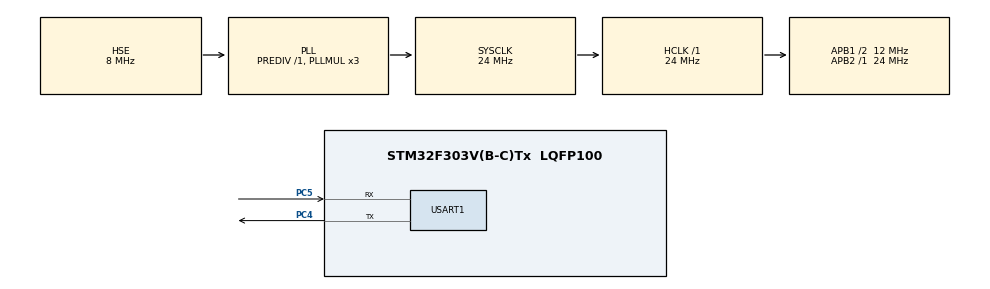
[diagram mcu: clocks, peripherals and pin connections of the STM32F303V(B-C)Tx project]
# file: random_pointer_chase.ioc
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Mcu.Family=STM32F3
Mcu.Name=STM32F303V(B-C)Tx
Mcu.Package=LQFP100
NVIC.PriorityGroup=NVIC_PRIORITYGROUP_4
NVIC.TIM2_IRQn=true\:0\:0\:false\:false\:true\:true\:true
PC4.Mode=Asynchronous
PC4.Signal=USART1_TX
PC5.Mode=Asynchronous
PC5.Signal=USART1_RX
PF0-OSC_IN.Mode=HSE-External-Oscillator
PF0-OSC_IN.Signal=RCC_OSC_IN
PF1-OSC_OUT.Mode=HSE-External-Oscillator
PF1-OSC_OUT.Signal=RCC_OSC_OUT
ProjectManager.HeapSize=0x200
ProjectManager.StackSize=0x400
ProjectManager.TargetToolchain=STM32CubeIDE
RCC.AHBFreq_Value=24000000
RCC.APB1CLKDivider=RCC_HCLK_DIV2
RCC.APB1Freq_Value=12000000
RCC.APB1TimFreq_Value=24000000
RCC.APB2Freq_Value=24000000
RCC.APB2TimFreq_Value=24000000
RCC.CortexFreq_Value=24000000
RCC.HCLKFreq_Value=24000000
RCC.HSE_VALUE=8000000
RCC.HSI_VALUE=8000000
RCC.LSE_VALUE=32768
RCC.PLLMUL=RCC_PLL_MUL3
RCC.PLLSourceVirtual=RCC_PLLSOURCE_HSE
RCC.SYSCLKFreq_VALUE=24000000
RCC.SYSCLKSourceVirtual=RCC_SYSCLKSOURCE_PLLCLK
RCC.USBFreq_Value=24000000
TIM2.AutoReloadPreload=TIM_AUTORELOAD_PRELOAD_DISABLE
TIM2.Period=(1000000-1)
TIM2.Prescaler=(24-1)
USART1.VirtualMode-Asynchronous=VM_ASYNC
VP_TIM2_VS_ClockSourceINT.Mode=Internal
board=custom

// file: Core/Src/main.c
/* USER CODE BEGIN Header */
/**
  ******************************************************************************
  * @file           : main.c
  * @brief          : Main program body
  ******************************************************************************
  * @attention
  *
  * <h2><center>&copy; Copyright (c) 2021 STMicroelectronics.
  * All rights reserved.</center></h2>
  *
  * This software component is licensed by ST under BSD 3-Clause license,
  * the "License"; You may not use this file except in compliance with the
  * License. You may obtain a copy of the License at:
  *                        opensource.org/licenses/BSD-3-Clause
  *
  ******************************************************************************
  */
/* USER CODE END Header */
#include "main.h"

/* USER CODE BEGIN Includes */

/*data size*/
#define POINTER_SIZE_2000

/*functions data*/
#define FUNCTIONS_DATA_ON_FLASH
//#define FUNCTIONS_DATA_ON_CCM

/*program allocation*/
#define PROGRAM_IN_CCM

/* USER CODE END Includes */

/* USER CODE BEGIN PTD */
#ifdef PROGRAM_IN_CCM
__attribute__((section(".ccmram")))
#endif
void random_pointer_chase_1000times( void * p0){
    void **this_pp = p0;
    for(int i = 0;i<1000;i++){
	  while(this_pp){
      this_pp = *this_pp;
	  }
    this_pp = p0;
  };

}

/* USER CODE END PTD */

/* USER CODE BEGIN PM */

#ifdef POINTER_SIZE_100
#ifdef FUNCTIONS_DATA_ON_CCM
  __attribute__((section(".ccmram")))
#endif
#ifdef FUNCTIONS_DATA_ON_FLASH
  const
#endif
   void *
#ifdef FUNCTIONS_DATA_ON_FLASH
  const
#endif
    pointers[100] = {
    &pointers[80], &pointers[65], &pointers[28], &pointers[92], &pointers[60], &pointers[22], &pointers[29], &pointers[21], &pointers[86], &pointers[79], &pointers[18], &pointers[56], &pointers[45], &pointers[35], &pointers[74], &pointers[48], &pointers[78], &pointers[67], &pointers[57], &pointers[71], &pointers[77], &pointers[15], &pointers[96], &pointers[43], &pointers[50], &pointers[20], &pointers[82], &pointers[58], &pointers[53], &pointers[47], &pointers[75], &pointers[3], &pointers[94], &pointers[95], &pointers[31], &pointers[44], &pointers[24], &pointers[23], &pointers[39], &pointers[37], &pointers[88], &pointers[97], &pointers[6], &pointers[52], &pointers[41], &pointers[55], &pointers[89], &pointers[76], &pointers[61], &pointers[70],
    &pointers[87], &pointers[30], &pointers[16], &pointers[36], &pointers[51], &pointers[25], &pointers[91], &pointers[17], &pointers[81], &pointers[34], &pointers[32], &pointers[90], &pointers[85], &pointers[11], &pointers[38], &pointers[99], &pointers[5], &pointers[1], &pointers[4], &pointers[59], &pointers[14], &pointers[13], &pointers[63], &pointers[27], &pointers[83], &pointers[8], &pointers[26], &pointers[73], &pointers[42], &pointers[62], &pointers[33], &pointers[66], &pointers[9], &pointers[2], &pointers[68], &pointers[93], &pointers[69], &pointers[10], &pointers[54], &pointers[84], &pointers[49], &pointers[19], NULL, &pointers[98], &pointers[7], &pointers[46], &pointers[64], &pointers[12], &pointers[40], &pointers[72]};

#endif

#ifdef POINTER_SIZE_200
#ifdef FUNCTIONS_DATA_ON_CCM
  __attribute__((section(".ccmram")))
#endif
#ifdef FUNCTIONS_DATA_ON_FLASH
  const
#endif
   void *
#ifdef FUNCTIONS_DATA_ON_FLASH
  const
#endif
    pointers[200] = {
    &pointers[160], &pointers[2], &pointers[54], &pointers[184], &pointers[56], &pointers[166], &pointers[93], &pointers[116], &pointers[120], &pointers[37], &pointers[176], &pointers[20], &pointers[179], &pointers[88], &pointers[41], &pointers[95], &pointers[97], &pointers[85], NULL, &pointers[36], &pointers[73], &pointers[7], &pointers[196], &pointers[191], &pointers[135], &pointers[82], &pointers[16], &pointers[147], &pointers[174], &pointers[96], &pointers[42], &pointers[35], &pointers[60], &pointers[34], &pointers[1], &pointers[103], &pointers[159], &pointers[123], &pointers[68], &pointers[173], &pointers[170], &pointers[29], &pointers[180], &pointers[158], &pointers[115], &pointers[198], &pointers[109], &pointers[100], &pointers[132], &pointers[156],
    &pointers[89], &pointers[139], &pointers[122], &pointers[172], &pointers[175], &pointers[104], &pointers[105], &pointers[15], &pointers[178], &pointers[69], &pointers[45], &pointers[13], &pointers[21], &pointers[171], &pointers[193], &pointers[28], &pointers[190], &pointers[50], &pointers[17], &pointers[25], &pointers[86], &pointers[101], &pointers[47], &pointers[62], &pointers[63], &pointers[81], &pointers[130], &pointers[6], &pointers[162], &pointers[124], &pointers[91], &pointers[51], &pointers[94], &pointers[65], &pointers[168], &pointers[78], &pointers[40], &pointers[141], &pointers[153], &pointers[125], &pointers[39], &pointers[79], &pointers[177], &pointers[107], &pointers[61], &pointers[59], &pointers[121], &pointers[32], &pointers[140], &pointers[77],
    &pointers[186], &pointers[199], &pointers[90], &pointers[119], &pointers[181], &pointers[72], &pointers[138], &pointers[157], &pointers[161], &pointers[52], &pointers[195], &pointers[126], &pointers[148], &pointers[169], &pointers[33], &pointers[133], &pointers[118], &pointers[102], &pointers[117], &pointers[18], &pointers[64], &pointers[189], &pointers[71], &pointers[150], &pointers[155], &pointers[185], &pointers[11], &pointers[24], &pointers[3], &pointers[149], &pointers[143], &pointers[67], &pointers[183], &pointers[113], &pointers[23], &pointers[26], &pointers[8], &pointers[112], &pointers[163], &pointers[53], &pointers[27], &pointers[80], &pointers[129], &pointers[5], &pointers[131], &pointers[57], &pointers[145], &pointers[182], &pointers[146], &pointers[187],
    &pointers[165], &pointers[49], &pointers[192], &pointers[144], &pointers[99], &pointers[48], &pointers[108], &pointers[38], &pointers[75], &pointers[188], &pointers[66], &pointers[58], &pointers[87], &pointers[31], &pointers[128], &pointers[83], &pointers[12], &pointers[136], &pointers[70], &pointers[84], &pointers[111], &pointers[22], &pointers[154], &pointers[152], &pointers[110], &pointers[43], &pointers[74], &pointers[197], &pointers[127], &pointers[44], &pointers[10], &pointers[137], &pointers[4], &pointers[134], &pointers[46], &pointers[106], &pointers[19], &pointers[76], &pointers[114], &pointers[98], &pointers[92], &pointers[164], &pointers[30], &pointers[14], &pointers[142], &pointers[55], &pointers[9], &pointers[167], &pointers[194], &pointers[151]};
#endif

#ifdef POINTER_SIZE_300
#ifdef FUNCTIONS_DATA_ON_CCM
  __attribute__((section(".ccmram")))
#endif
#ifdef FUNCTIONS_DATA_ON_FLASH
  const
#endif
   void *
#ifdef FUNCTIONS_DATA_ON_FLASH
  const
#endif
    pointers[300] = {
    &pointers[131], &pointers[3], &pointers[204], &pointers[108], &pointers[99], &pointers[141], &pointers[192], &pointers[111], &pointers[77], &pointers[61], &pointers[268], &pointers[166], &pointers[185], &pointers[172], &pointers[74], &pointers[239], &pointers[246], &pointers[267], &pointers[83], &pointers[159], &pointers[231], &pointers[264], &pointers[262], &pointers[232], &pointers[54], &pointers[190], &pointers[165], &pointers[81], &pointers[245], &pointers[113], &pointers[251], &pointers[194], &pointers[295], &pointers[167], &pointers[145], &pointers[225], &pointers[256], &pointers[72], &pointers[297], &pointers[177], &pointers[229], &pointers[57], &pointers[13], &pointers[240], &pointers[112], &pointers[248], &pointers[296], &pointers[160], &pointers[234], &pointers[147],
    &pointers[20], &pointers[31], &pointers[211], &pointers[294], &pointers[88], &pointers[205], &pointers[26], &pointers[283], &pointers[191], &pointers[244], &pointers[136], &pointers[243], &pointers[218], &pointers[119], &pointers[142], &pointers[68], &pointers[6], &pointers[56], &pointers[1], &pointers[23], &pointers[293], &pointers[140], &pointers[228], &pointers[285], &pointers[169], &pointers[207], &pointers[10], &pointers[233], &pointers[210], &pointers[124], &pointers[91], &pointers[58], &pointers[37], &pointers[299], &pointers[196], &pointers[86], &pointers[149], &pointers[250], &pointers[278], &pointers[132], &pointers[126], &pointers[247], &pointers[217], &pointers[252], &pointers[200], &pointers[76], &pointers[170], &pointers[265], &pointers[291], &pointers[41],
    &pointers[173], &pointers[197], &pointers[105], &pointers[11], &pointers[5], &pointers[286], &pointers[287], &pointers[43], &pointers[282], &pointers[263], &pointers[222], &pointers[209], &pointers[96], &pointers[130], &pointers[55], &pointers[84], &pointers[257], &pointers[216], &pointers[98], &pointers[89], &pointers[224], &pointers[181], &pointers[29], &pointers[180], &pointers[179], &pointers[175], &pointers[50], &pointers[195], &pointers[27], &pointers[298], &pointers[189], &pointers[184], &pointers[237], &pointers[120], &pointers[178], &pointers[273], &pointers[255], &pointers[220], &pointers[33], &pointers[8], &pointers[188], &pointers[202], &pointers[134], &pointers[198], &pointers[94], &pointers[148], &pointers[164], &pointers[69], &pointers[106], &pointers[161],
    &pointers[36], &pointers[271], &pointers[109], &pointers[12], &pointers[137], &pointers[151], &pointers[143], &pointers[93], &pointers[163], &pointers[49], &pointers[51], &pointers[102], &pointers[45], &pointers[249], &pointers[115], &pointers[59], &pointers[213], &pointers[183], &pointers[103], &pointers[206], &pointers[16], &pointers[288], &pointers[154], &pointers[158], &pointers[182], &pointers[123], &pointers[277], &pointers[230], &pointers[236], &pointers[292], &pointers[75], &pointers[46], &pointers[87], &pointers[60], &pointers[272], &pointers[107], &pointers[71], &pointers[34], &pointers[238], &pointers[212], &pointers[67], &pointers[241], &pointers[92], &pointers[254], &pointers[63], &pointers[279], &pointers[284], &pointers[153], &pointers[125], &pointers[150],
    &pointers[82], &pointers[259], &pointers[269], &pointers[35], &pointers[138], &pointers[133], &pointers[25], &pointers[52], &pointers[152], &pointers[144], &pointers[155], &pointers[19], &pointers[139], &pointers[114], &pointers[4], &pointers[18], &pointers[281], &pointers[104], &pointers[274], &pointers[40], &pointers[9], &pointers[28], &pointers[70], &pointers[95], &pointers[110], &pointers[260], &pointers[171], &pointers[21], &pointers[65], &pointers[275], &pointers[42], &pointers[215], &pointers[64], &pointers[214], &pointers[121], &pointers[227], &pointers[203], &pointers[135], &pointers[176], &pointers[128], &pointers[38], &pointers[127], &pointers[280], &pointers[201], &pointers[32], &pointers[223], &pointers[290], &pointers[79], &pointers[73], &pointers[219],
    &pointers[80], &pointers[253], &pointers[186], NULL, &pointers[168], &pointers[162], &pointers[146], &pointers[289], &pointers[174], &pointers[117], &pointers[129], &pointers[97], &pointers[30], &pointers[100], &pointers[39], &pointers[270], &pointers[187], &pointers[78], &pointers[24], &pointers[261], &pointers[116], &pointers[258], &pointers[15], &pointers[221], &pointers[90], &pointers[199], &pointers[156], &pointers[235], &pointers[157], &pointers[53], &pointers[14], &pointers[226], &pointers[85], &pointers[242], &pointers[2], &pointers[118], &pointers[101], &pointers[44], &pointers[266], &pointers[47], &pointers[276], &pointers[193], &pointers[48], &pointers[62], &pointers[7], &pointers[22], &pointers[66], &pointers[17], &pointers[208], &pointers[122]};
#endif

#ifdef POINTER_SIZE_400
#ifdef FUNCTIONS_DATA_ON_CCM
  __attribute__((section(".ccmram")))
#endif
#ifdef FUNCTIONS_DATA_ON_FLASH
  const
#endif
   void *
#ifdef FUNCTIONS_DATA_ON_FLASH
  const
#endif
    pointers[400] = {
    &pointers[319], &pointers[3], &pointers[306], &pointers[108], &pointers[171], &pointers[232], &pointers[376], &pointers[375], &pointers[345], &pointers[381], &pointers[282], &pointers[223], &pointers[185], &pointers[221], &pointers[35], &pointers[239], &pointers[217], &pointers[122], &pointers[318], &pointers[222], &pointers[55], &pointers[257], NULL, &pointers[303], &pointers[93], &pointers[42], &pointers[18], &pointers[81], &pointers[44], &pointers[268], &pointers[132], &pointers[168], &pointers[176], &pointers[397], &pointers[170], &pointers[220], &pointers[394], &pointers[72], &pointers[261], &pointers[16], &pointers[320], &pointers[77], &pointers[208], &pointers[51], &pointers[112], &pointers[116], &pointers[395], &pointers[107], &pointers[160], &pointers[341],
    &pointers[4], &pointers[204], &pointers[36], &pointers[294], &pointers[60], &pointers[323], &pointers[189], &pointers[240], &pointers[191], &pointers[140], &pointers[313], &pointers[126], &pointers[271], &pointers[286], &pointers[256], &pointers[68], &pointers[147], &pointers[252], &pointers[1], &pointers[100], &pointers[399], &pointers[262], &pointers[317], &pointers[21], &pointers[205], &pointers[136], &pointers[288], &pointers[329], &pointers[283], &pointers[351], &pointers[64], &pointers[58], &pointers[37], &pointers[25], &pointers[190], &pointers[86], &pointers[149], &pointers[290], &pointers[167], &pointers[349], &pointers[173], &pointers[30], &pointers[178], &pointers[347], &pointers[200], &pointers[326], &pointers[39], &pointers[211], &pointers[295], &pointers[324],
    &pointers[331], &pointers[197], &pointers[277], &pointers[32], &pointers[38], &pointers[371], &pointers[28], &pointers[175], &pointers[374], &pointers[146], &pointers[382], &pointers[209], &pointers[96], &pointers[212], &pointers[314], &pointers[322], &pointers[311], &pointers[274], &pointers[52], &pointers[74], &pointers[291], &pointers[104], &pointers[393], &pointers[71], &pointers[307], &pointers[266], &pointers[237], &pointers[195], &pointers[333], &pointers[302], &pointers[270], &pointers[380], &pointers[344], &pointers[296], &pointers[236], &pointers[80], &pointers[34], &pointers[46], &pointers[130], &pointers[124], &pointers[308], &pointers[265], &pointers[280], &pointers[66], &pointers[94], &pointers[244], &pointers[305], &pointers[224], &pointers[259], &pointers[161],
    &pointers[392], &pointers[337], &pointers[19], &pointers[12], &pointers[14], &pointers[309], &pointers[198], &pointers[247], &pointers[114], &pointers[182], &pointers[163], &pointers[102], &pointers[95], &pointers[327], &pointers[316], &pointers[89], &pointers[370], &pointers[287], &pointers[281], &pointers[335], &pointers[155], &pointers[22], &pointers[289], &pointers[165], &pointers[338], &pointers[300], &pointers[358], &pointers[263], &pointers[151], &pointers[98], &pointers[275], &pointers[258], &pointers[157], &pointers[59], &pointers[354], &pointers[213], &pointers[76], &pointers[369], &pointers[193], &pointers[152], &pointers[225], &pointers[241], &pointers[293], &pointers[297], &pointers[315], &pointers[279], &pointers[346], &pointers[153], &pointers[246], &pointers[92],
    &pointers[82], &pointers[141], &pointers[106], &pointers[120], &pointers[226], &pointers[166], &pointers[363], &pointers[10], &pointers[17], &pointers[144], &pointers[26], &pointers[137], &pointers[57], &pointers[357], &pointers[33], &pointers[188], &pointers[340], &pointers[359], &pointers[196], &pointers[245], &pointers[139], &pointers[143], &pointers[47], &pointers[385], &pointers[235], &pointers[119], &pointers[73], &pointers[383], &pointers[65], &pointers[365], &pointers[202], &pointers[284], &pointers[24], &pointers[278], &pointers[216], &pointers[384], &pointers[125], &pointers[177], &pointers[88], &pointers[128], &pointers[11], &pointers[127], &pointers[91], &pointers[386], &pointers[330], &pointers[134], &pointers[304], &pointers[162], &pointers[83], &pointers[362],
    &pointers[99], &pointers[250], &pointers[312], &pointers[172], &pointers[353], &pointers[388], &pointers[179], &pointers[233], &pointers[367], &pointers[138], &pointers[273], &pointers[97], &pointers[121], &pointers[328], &pointers[110], &pointers[332], &pointers[187], &pointers[206], &pointers[253], &pointers[129], &pointers[264], &pointers[169], &pointers[15], &pointers[199], &pointers[219], &pointers[231], &pointers[113], &pointers[348], &pointers[390], &pointers[53], &pointers[48], &pointers[361], &pointers[215], &pointers[373], &pointers[210], &pointers[368], &pointers[214], &pointers[355], &pointers[142], &pointers[67], &pointers[23], &pointers[150], &pointers[180], &pointers[352], &pointers[389], &pointers[364], &pointers[339], &pointers[5], &pointers[156], &pointers[45],
    &pointers[186], &pointers[2], &pointers[56], &pointers[70], &pointers[103], &pointers[115], &pointers[174], &pointers[62], &pointers[243], &pointers[301], &pointers[234], &pointers[356], &pointers[145], &pointers[49], &pointers[63], &pointers[343], &pointers[109], &pointers[366], &pointers[148], &pointers[131], &pointers[6], &pointers[105], &pointers[13], &pointers[255], &pointers[227], &pointers[230], &pointers[242], &pointers[350], &pointers[269], &pointers[248], &pointers[325], &pointers[292], &pointers[260], &pointers[27], &pointers[272], &pointers[54], &pointers[298], &pointers[9], &pointers[159], &pointers[43], &pointers[29], &pointers[194], &pointers[20], &pointers[387], &pointers[396], &pointers[276], &pointers[254], &pointers[61], &pointers[321], &pointers[299],
    &pointers[41], &pointers[372], &pointers[158], &pointers[135], &pointers[379], &pointers[360], &pointers[133], &pointers[75], &pointers[183], &pointers[285], &pointers[267], &pointers[118], &pointers[229], &pointers[84], &pointers[398], &pointers[238], &pointers[228], &pointers[249], &pointers[117], &pointers[123], &pointers[90], &pointers[101], &pointers[181], &pointers[8], &pointers[85], &pointers[111], &pointers[50], &pointers[87], &pointers[218], &pointers[334], &pointers[184], &pointers[79], &pointers[336], &pointers[378], &pointers[203], &pointers[154], &pointers[342], &pointers[31], &pointers[192], &pointers[7], &pointers[78], &pointers[164], &pointers[69], &pointers[310], &pointers[391], &pointers[377], &pointers[207], &pointers[251], &pointers[40], &pointers[201]};

#endif

#ifdef POINTER_SIZE_500
#ifdef FUNCTIONS_DATA_ON_CCM
  __attribute__((section(".ccmram")))
#endif
#ifdef FUNCTIONS_DATA_ON_FLASH
  const
#endif
   void *
#ifdef FUNCTIONS_DATA_ON_FLASH
  const
#endif
    pointers[500] = {
    &pointers[319], &pointers[447], &pointers[306], &pointers[108], &pointers[16], &pointers[232], &pointers[243], &pointers[375], &pointers[291], &pointers[218], &pointers[282], &pointers[121], &pointers[185], &pointers[118], &pointers[35], &pointers[492], &pointers[425], &pointers[122], &pointers[351], &pointers[222], &pointers[469], &pointers[286], &pointers[430], &pointers[382], &pointers[413], &pointers[42], &pointers[114], &pointers[462], &pointers[84], &pointers[327], &pointers[132], &pointers[332], &pointers[38], &pointers[183], &pointers[170], &pointers[330], &pointers[345], &pointers[72], &pointers[340], &pointers[275], &pointers[63], &pointers[435], &pointers[308], &pointers[51], &pointers[158], &pointers[202], &pointers[252], &pointers[107], &pointers[160], &pointers[66],
    &pointers[323], &pointers[457], &pointers[346], &pointers[294], &pointers[446], &pointers[87], &pointers[302], &pointers[472], &pointers[191], &pointers[206], &pointers[45], &pointers[126], &pointers[4], &pointers[119], &pointers[488], &pointers[68], &pointers[168], &pointers[289], &pointers[1], &pointers[466], &pointers[388], &pointers[112], &pointers[317], &pointers[233], &pointers[316], &pointers[136], &pointers[396], &pointers[410], &pointers[432], &pointers[74], &pointers[314], &pointers[58], &pointers[391], &pointers[25], &pointers[139], &pointers[86], &pointers[149], &pointers[223], &pointers[480], &pointers[231], &pointers[98], &pointers[30], &pointers[256], &pointers[320], &pointers[474], &pointers[407], &pointers[448], &pointers[110], &pointers[421], &pointers[156],
    &pointers[109], &pointers[197], &pointers[277], &pointers[418], &pointers[454], &pointers[479], &pointers[221], &pointers[175], &pointers[397], &pointers[355], &pointers[443], &pointers[209], &pointers[487], &pointers[259], &pointers[415], &pointers[125], &pointers[60], &pointers[69], &pointers[261], &pointers[230], &pointers[90], &pointers[299], &pointers[305], &pointers[295], &pointers[50], &pointers[328], &pointers[237], &pointers[195], &pointers[333], &pointers[378], &pointers[344], &pointers[380], &pointers[428], &pointers[171], &pointers[303], &pointers[100], &pointers[34], &pointers[467], &pointers[404], &pointers[192], &pointers[264], &pointers[150], &pointers[280], &pointers[64], &pointers[94], &pointers[138], &pointers[99], &pointers[255], &pointers[257], &pointers[161],
    &pointers[475], &pointers[73], &pointers[19], &pointers[12], &pointers[28], &pointers[419], &pointers[324], &pointers[247], &pointers[459], &pointers[182], &pointers[352], &pointers[102], &pointers[95], &pointers[495], &pointers[70], &pointers[322], &pointers[71], &pointers[304], &pointers[227], &pointers[134], &pointers[155], &pointers[461], &pointers[364], &pointers[468], &pointers[422], &pointers[376], &pointers[217], &pointers[263], &pointers[21], &pointers[270], &pointers[89], &pointers[145], &pointers[157], &pointers[18], &pointers[408], &pointers[213], &pointers[76], &pointers[463], &pointers[193], &pointers[152], &pointers[146], &pointers[241], &pointers[356], &pointers[297], &pointers[273], &pointers[279], &pointers[455], &pointers[153], &pointers[245], &pointers[366],
    &pointers[82], &pointers[342], &pointers[203], &pointers[389], &pointers[137], &pointers[385], &pointers[402], &pointers[10], &pointers[17], &pointers[144], &pointers[180], &pointers[96], &pointers[55], &pointers[442], &pointers[262], &pointers[188], &pointers[424], &pointers[405], &pointers[244], &pointers[123], &pointers[336], &pointers[416], &pointers[47], &pointers[476], &pointers[9], &pointers[154], &pointers[307], &pointers[103], &pointers[65], &pointers[360], &pointers[452], &pointers[288], &pointers[24], &pointers[499], &pointers[216], &pointers[130], &pointers[481], &pointers[177], &pointers[148], &pointers[398], &pointers[219], &pointers[445], &pointers[361], &pointers[490], &pointers[491], &pointers[374], &pointers[141], &pointers[357], &pointers[83], &pointers[423],
    &pointers[353], &pointers[43], &pointers[140], &pointers[172], &pointers[104], &pointers[59], &pointers[412], &pointers[284], &pointers[427], &pointers[271], &pointers[115], &pointers[226], &pointers[337], &pointers[456], &pointers[281], &pointers[22], &pointers[420], &pointers[287], &pointers[311], &pointers[129], &pointers[335], &pointers[365], &pointers[15], &pointers[92], &pointers[208], &pointers[438], &pointers[166], &pointers[348], &pointers[251], &pointers[53], &pointers[48], &pointers[258], &pointers[215], &pointers[106], &pointers[179], &pointers[54], &pointers[267], &pointers[325], &pointers[326], &pointers[449], &pointers[484], &pointers[349], &pointers[201], &pointers[240], &pointers[482], &pointers[178], &pointers[6], &pointers[5], &pointers[439], &pointers[329],
    &pointers[290], &pointers[2], &pointers[189], &pointers[20], &pointers[238], &pointers[377], &pointers[436], &pointers[79], &pointers[274], &pointers[301], &pointers[236], &pointers[250], &pointers[278], &pointers[186], &pointers[32], &pointers[450], &pointers[371], &pointers[453], &pointers[205], &pointers[131], &pointers[486], &pointers[105], &pointers[116], &pointers[460], &pointers[173], &pointers[44], &pointers[312], &pointers[338], &pointers[39], &pointers[14], &pointers[458], &pointers[190], &pointers[151], &pointers[27], &pointers[473], &pointers[210], &pointers[292], &pointers[265], &pointers[253], &pointers[489], &pointers[381], &pointers[181], &pointers[315], &pointers[300], &pointers[260], &pointers[390], &pointers[478], &pointers[31], &pointers[321], &pointers[437],
    &pointers[411], &pointers[187], &pointers[163], &pointers[246], &pointers[483], &pointers[276], &pointers[97], &pointers[162], &pointers[296], &pointers[477], &pointers[198], &pointers[91], &pointers[229], &pointers[174], &pointers[67], &pointers[57], &pointers[164], &pointers[368], &pointers[470], &pointers[26], &pointers[225], &pointers[414], &pointers[52], &pointers[234], &pointers[386], &pointers[111], &pointers[313], &pointers[373], &pointers[56], &pointers[334], &pointers[184], &pointers[283], &pointers[88], &pointers[46], &pointers[496], &pointers[370], &pointers[343], &pointers[169], &pointers[8], &pointers[147], &pointers[387], &pointers[409], &pointers[367], &pointers[200], &pointers[359], &pointers[11], &pointers[142], &pointers[465], &pointers[493], &pointers[362],
    &pointers[41], &pointers[358], &pointers[266], &pointers[318], &pointers[196], &pointers[395], &pointers[199], &pointers[242], &pointers[354], &pointers[37], &pointers[248], &pointers[341], &pointers[383], &pointers[93], &pointers[417], &pointers[13], &pointers[117], &pointers[214], &pointers[441], &pointers[309], &pointers[372], &pointers[392], &pointers[159], &pointers[401], &pointers[29], &pointers[80], &pointers[124], &pointers[33], &pointers[384], &pointers[298], &pointers[49], &pointers[379], &pointers[406], &pointers[204], &pointers[399], &pointers[77], &pointers[363], &pointers[113], &pointers[485], &pointers[403], &pointers[133], &pointers[224], &pointers[75], &pointers[339], &pointers[23], &pointers[127], &pointers[498], &pointers[3], &pointers[254], &pointers[212],
    &pointers[369], &pointers[429], &pointers[62], &pointers[228], &pointers[434], &pointers[451], &pointers[269], &pointers[293], &pointers[426], &pointers[440], &pointers[471], &pointers[78], &pointers[81], &pointers[249], &pointers[40], &pointers[85], &pointers[36], &pointers[444], &pointers[285], &pointers[143], &pointers[497], &pointers[120], &pointers[176], &pointers[272], &pointers[393], &pointers[394], &pointers[347], &pointers[194], &pointers[220], &pointers[494], &pointers[135], &pointers[350], &pointers[7], &pointers[431], &pointers[310], &pointers[165], &pointers[61], NULL, &pointers[235], &pointers[331], &pointers[167], &pointers[433], &pointers[239], &pointers[128], &pointers[101], &pointers[400], &pointers[207], &pointers[211], &pointers[464], &pointers[268]};
#endif

#ifdef POINTER_SIZE_750
#ifdef FUNCTIONS_DATA_ON_CCM
  __attribute__((section(".ccmram")))
#endif
#ifdef FUNCTIONS_DATA_ON_FLASH
  const
#endif
   void *
#ifdef FUNCTIONS_DATA_ON_FLASH
  const
#endif
    pointers[750] = {
    &pointers[638], &pointers[558], &pointers[6], &pointers[436], &pointers[611], &pointers[168], &pointers[215], &pointers[423], &pointers[428], &pointers[564], &pointers[464], &pointers[520], &pointers[486], &pointers[63], &pointers[222], &pointers[235], &pointers[682], &pointers[313], &pointers[237], &pointers[563], &pointers[580], &pointers[70], &pointers[327], &pointers[370], &pointers[367], &pointers[567], &pointers[64], &pointers[261], &pointers[457], &pointers[201], &pointers[477], &pointers[84], &pointers[352], &pointers[244], &pointers[506], &pointers[599], &pointers[628], &pointers[644], &pointers[444], &pointers[733], &pointers[41], &pointers[542], &pointers[341], &pointers[483], &pointers[619], &pointers[403], &pointers[332], &pointers[552], &pointers[186], &pointers[635],
    &pointers[83], &pointers[410], &pointers[51], &pointers[460], &pointers[161], &pointers[304], &pointers[167], &pointers[163], &pointers[34], &pointers[263], &pointers[112], &pointers[431], &pointers[249], &pointers[338], &pointers[402], &pointers[365], &pointers[268], &pointers[340], &pointers[318], &pointers[57], &pointers[521], &pointers[379], &pointers[42], &pointers[568], &pointers[143], &pointers[86], &pointers[391], &pointers[703], &pointers[259], &pointers[218], &pointers[565], &pointers[153], &pointers[451], &pointers[616], &pointers[200], &pointers[404], &pointers[408], &pointers[258], &pointers[22], &pointers[291], &pointers[536], &pointers[254], &pointers[504], &pointers[248], &pointers[214], &pointers[320], &pointers[117], &pointers[91], &pointers[8], &pointers[307],
    &pointers[744], &pointers[576], &pointers[509], &pointers[570], &pointers[344], &pointers[588], &pointers[355], NULL, &pointers[389], &pointers[337], &pointers[173], &pointers[604], &pointers[321], &pointers[508], &pointers[592], &pointers[584], &pointers[381], &pointers[189], &pointers[137], &pointers[123], &pointers[229], &pointers[131], &pointers[252], &pointers[430], &pointers[514], &pointers[243], &pointers[587], &pointers[27], &pointers[630], &pointers[586], &pointers[136], &pointers[534], &pointers[360], &pointers[606], &pointers[578], &pointers[308], &pointers[2], &pointers[44], &pointers[80], &pointers[518], &pointers[388], &pointers[125], &pointers[66], &pointers[633], &pointers[743], &pointers[465], &pointers[709], &pointers[721], &pointers[685], &pointers[466],
    &pointers[271], &pointers[737], &pointers[658], &pointers[317], &pointers[591], &pointers[49], &pointers[479], &pointers[478], &pointers[655], &pointers[455], &pointers[405], &pointers[116], &pointers[384], &pointers[623], &pointers[74], &pointers[217], &pointers[50], &pointers[529], &pointers[88], &pointers[468], &pointers[171], &pointers[297], &pointers[701], &pointers[445], &pointers[535], &pointers[230], &pointers[663], &pointers[461], &pointers[188], &pointers[223], &pointers[195], &pointers[59], &pointers[81], &pointers[12], &pointers[512], &pointers[92], &pointers[639], &pointers[399], &pointers[311], &pointers[503], &pointers[679], &pointers[686], &pointers[1], &pointers[220], &pointers[106], &pointers[690], &pointers[458], &pointers[82], &pointers[376], &pointers[627],
    &pointers[617], &pointers[722], &pointers[393], &pointers[632], &pointers[553], &pointers[688], &pointers[471], &pointers[569], &pointers[720], &pointers[596], &pointers[724], &pointers[652], &pointers[620], &pointers[134], &pointers[349], &pointers[221], &pointers[264], &pointers[142], &pointers[300], &pointers[459], &pointers[727], &pointers[170], &pointers[418], &pointers[411], &pointers[194], &pointers[572], &pointers[539], &pointers[120], &pointers[126], &pointers[556], &pointers[608], &pointers[400], &pointers[694], &pointers[740], &pointers[438], &pointers[335], &pointers[551], &pointers[729], &pointers[443], &pointers[180], &pointers[73], &pointers[351], &pointers[160], &pointers[548], &pointers[609], &pointers[102], &pointers[363], &pointers[198], &pointers[100], &pointers[294],
    &pointers[26], &pointers[138], &pointers[474], &pointers[390], &pointers[75], &pointers[129], &pointers[665], &pointers[654], &pointers[292], &pointers[149], &pointers[199], &pointers[738], &pointers[368], &pointers[24], &pointers[293], &pointers[530], &pointers[331], &pointers[462], &pointers[72], &pointers[348], &pointers[90], &pointers[67], &pointers[301], &pointers[725], &pointers[422], &pointers[96], &pointers[677], &pointers[453], &pointers[29], &pointers[528], &pointers[672], &pointers[299], &pointers[315], &pointers[559], &pointers[234], &pointers[555], &pointers[127], &pointers[187], &pointers[498], &pointers[329], &pointers[637], &pointers[519], &pointers[396], &pointers[159], &pointers[119], &pointers[678], &pointers[513], &pointers[322], &pointers[579], &pointers[482],
    &pointers[523], &pointers[634], &pointers[145], &pointers[38], &pointers[540], &pointers[603], &pointers[23], &pointers[316], &pointers[121], &pointers[618], &pointers[278], &pointers[546], &pointers[47], &pointers[575], &pointers[493], &pointers[155], &pointers[39], &pointers[496], &pointers[364], &pointers[228], &pointers[325], &pointers[140], &pointers[204], &pointers[449], &pointers[190], &pointers[680], &pointers[491], &pointers[726], &pointers[705], &pointers[276], &pointers[412], &pointers[524], &pointers[554], &pointers[247], &pointers[583], &pointers[148], &pointers[650], &pointers[739], &pointers[319], &pointers[487], &pointers[309], &pointers[336], &pointers[104], &pointers[213], &pointers[330], &pointers[645], &pointers[139], &pointers[68], &pointers[585], &pointers[526],
    &pointers[676], &pointers[670], &pointers[595], &pointers[525], &pointers[419], &pointers[566], &pointers[124], &pointers[549], &pointers[108], &pointers[177], &pointers[60], &pointers[533], &pointers[661], &pointers[497], &pointers[314], &pointers[36], &pointers[357], &pointers[414], &pointers[708], &pointers[114], &pointers[425], &pointers[489], &pointers[152], &pointers[288], &pointers[605], &pointers[386], &pointers[394], &pointers[303], &pointers[32], &pointers[78], &pointers[472], &pointers[481], &pointers[625], &pointers[723], &pointers[362], &pointers[55], &pointers[593], &pointers[545], &pointers[358], &pointers[231], &pointers[557], &pointers[647], &pointers[328], &pointers[306], &pointers[101], &pointers[260], &pointers[707], &pointers[704], &pointers[251], &pointers[164],
    &pointers[286], &pointers[191], &pointers[113], &pointers[749], &pointers[648], &pointers[85], &pointers[397], &pointers[718], &pointers[270], &pointers[206], &pointers[356], &pointers[53], &pointers[689], &pointers[574], &pointers[19], &pointers[242], &pointers[33], &pointers[289], &pointers[287], &pointers[359], &pointers[691], &pointers[339], &pointers[598], &pointers[273], &pointers[110], &pointers[710], &pointers[502], &pointers[176], &pointers[219], &pointers[375], &pointers[511], &pointers[302], &pointers[693], &pointers[45], &pointers[207], &pointers[470], &pointers[507], &pointers[323], &pointers[469], &pointers[702], &pointers[216], &pointers[224], &pointers[494], &pointers[516], &pointers[94], &pointers[382], &pointers[600], &pointers[17], &pointers[13], &pointers[193],
    &pointers[56], &pointers[305], &pointers[659], &pointers[437], &pointers[385], &pointers[227], &pointers[130], &pointers[69], &pointers[245], &pointers[295], &pointers[383], &pointers[374], &pointers[433], &pointers[192], &pointers[48], &pointers[174], &pointers[135], &pointers[432], &pointers[89], &pointers[98], &pointers[732], &pointers[560], &pointers[255], &pointers[277], &pointers[353], &pointers[296], &pointers[522], &pointers[256], &pointers[342], &pointers[527], &pointers[748], &pointers[253], &pointers[669], &pointers[232], &pointers[181], &pointers[250], &pointers[612], &pointers[450], &pointers[501], &pointers[290], &pointers[643], &pointers[281], &pointers[109], &pointers[324], &pointers[144], &pointers[577], &pointers[166], &pointers[197], &pointers[272], &pointers[607],
    &pointers[326], &pointers[282], &pointers[488], &pointers[46], &pointers[279], &pointers[133], &pointers[343], &pointers[624], &pointers[446], &pointers[312], &pointers[735], &pointers[532], &pointers[684], &pointers[366], &pointers[440], &pointers[696], &pointers[350], &pointers[77], &pointers[99], &pointers[16], &pointers[158], &pointers[7], &pointers[71], &pointers[25], &pointers[594], &pointers[681], &pointers[626], &pointers[582], &pointers[562], &pointers[473], &pointers[666], &pointers[146], &pointers[687], &pointers[345], &pointers[434], &pointers[590], &pointers[203], &pointers[31], &pointers[257], &pointers[492], &pointers[629], &pointers[226], &pointers[407], &pointers[30], &pointers[103], &pointers[184], &pointers[107], &pointers[416], &pointers[398], &pointers[354],
    &pointers[241], &pointers[651], &pointers[421], &pointers[695], &pointers[5], &pointers[442], &pointers[621], &pointers[105], &pointers[208], &pointers[95], &pointers[18], &pointers[37], &pointers[515], &pointers[429], &pointers[154], &pointers[406], &pointers[369], &pointers[118], &pointers[698], &pointers[275], &pointers[128], &pointers[622], &pointers[43], &pointers[541], &pointers[717], &pointers[730], &pointers[499], &pointers[132], &pointers[715], &pointers[674], &pointers[640], &pointers[417], &pointers[415], &pointers[475], &pointers[480], &pointers[454], &pointers[11], &pointers[21], &pointers[741], &pointers[298], &pointers[500], &pointers[274], &pointers[490], &pointers[10], &pointers[9], &pointers[692], &pointers[667], &pointers[615], &pointers[435], &pointers[697],
    &pointers[517], &pointers[4], &pointers[734], &pointers[380], &pointers[377], &pointers[531], &pointers[550], &pointers[156], &pointers[269], &pointers[653], &pointers[179], &pointers[347], &pointers[334], &pointers[426], &pointers[246], &pointers[266], &pointers[547], &pointers[87], &pointers[601], &pointers[361], &pointers[35], &pointers[40], &pointers[76], &pointers[93], &pointers[736], &pointers[61], &pointers[372], &pointers[20], &pointers[373], &pointers[97], &pointers[178], &pointers[212], &pointers[711], &pointers[719], &pointers[183], &pointers[280], &pointers[205], &pointers[427], &pointers[262], &pointers[700], &pointers[746], &pointers[210], &pointers[673], &pointers[544], &pointers[731], &pointers[485], &pointers[239], &pointers[505], &pointers[413], &pointers[467],
    &pointers[169], &pointers[172], &pointers[209], &pointers[649], &pointers[111], &pointers[147], &pointers[747], &pointers[495], &pointers[283], &pointers[225], &pointers[52], &pointers[476], &pointers[671], &pointers[310], &pointers[714], &pointers[54], &pointers[610], &pointers[657], &pointers[543], &pointers[151], &pointers[447], &pointers[378], &pointers[589], &pointers[613], &pointers[420], &pointers[699], &pointers[683], &pointers[240], &pointers[333], &pointers[484], &pointers[182], &pointers[538], &pointers[233], &pointers[664], &pointers[185], &pointers[157], &pointers[742], &pointers[346], &pointers[713], &pointers[573], &pointers[561], &pointers[712], &pointers[62], &pointers[58], &pointers[28], &pointers[641], &pointers[65], &pointers[285], &pointers[196], &pointers[236],
    &pointers[122], &pointers[395], &pointers[642], &pointers[631], &pointers[597], &pointers[675], &pointers[371], &pointers[401], &pointers[668], &pointers[706], &pointers[150], &pointers[571], &pointers[581], &pointers[510], &pointers[716], &pointers[424], &pointers[284], &pointers[79], &pointers[165], &pointers[456], &pointers[439], &pointers[448], &pointers[452], &pointers[267], &pointers[202], &pointers[141], &pointers[662], &pointers[602], &pointers[238], &pointers[441], &pointers[660], &pointers[656], &pointers[728], &pointers[175], &pointers[614], &pointers[162], &pointers[115], &pointers[387], &pointers[265], &pointers[409], &pointers[537], &pointers[14], &pointers[211], &pointers[636], &pointers[745], &pointers[646], &pointers[3], &pointers[463], &pointers[15], &pointers[392]};

#endif

#ifdef POINTER_SIZE_1000
#ifdef FUNCTIONS_DATA_ON_CCM
  __attribute__((section(".ccmram")))
#endif
#ifdef FUNCTIONS_DATA_ON_FLASH
  const
#endif
   void *
#ifdef FUNCTIONS_DATA_ON_FLASH
  const
#endif
    pointers[1000] = {
    &pointers[638], &pointers[719], &pointers[893], &pointers[259], &pointers[611], &pointers[542], &pointers[215], &pointers[86], &pointers[674], &pointers[996], &pointers[464], &pointers[408], &pointers[486], &pointers[469], &pointers[749], &pointers[610], &pointers[692], &pointers[949], &pointers[103], &pointers[563], &pointers[917], &pointers[327], &pointers[238], &pointers[370], &pointers[768], &pointers[125], &pointers[64], &pointers[342], &pointers[476], &pointers[201], &pointers[861], &pointers[737], &pointers[608], &pointers[244], &pointers[506], &pointers[762], &pointers[836], &pointers[426], &pointers[444], &pointers[216], &pointers[316], &pointers[140], &pointers[413], &pointers[483], &pointers[530], &pointers[441], &pointers[346], &pointers[162], &pointers[909], &pointers[369],
    &pointers[83], &pointers[100], &pointers[99], &pointers[218], &pointers[923], &pointers[300], &pointers[137], &pointers[757], &pointers[654], &pointers[263], &pointers[754], &pointers[431], &pointers[126], &pointers[113], &pointers[811], &pointers[365], &pointers[650], &pointers[340], &pointers[318], &pointers[810], &pointers[770], &pointers[236], &pointers[508], &pointers[39], &pointers[143], &pointers[518], &pointers[517], &pointers[622], &pointers[292], &pointers[689], &pointers[82], &pointers[642], &pointers[473], &pointers[616], &pointers[18], &pointers[940], &pointers[120], &pointers[892], &pointers[991], &pointers[448], &pointers[107], &pointers[796], &pointers[504], &pointers[203], &pointers[214], &pointers[320], &pointers[104], &pointers[803], &pointers[854], &pointers[80],
    &pointers[157], &pointers[596], &pointers[227], &pointers[13], &pointers[101], &pointers[588], &pointers[537], &pointers[631], &pointers[771], &pointers[72], &pointers[173], &pointers[604], &pointers[918], &pointers[594], &pointers[837], &pointers[384], &pointers[381], &pointers[462], &pointers[735], &pointers[584], &pointers[522], &pointers[131], &pointers[774], &pointers[422], &pointers[90], &pointers[455], &pointers[51], &pointers[400], &pointers[943], &pointers[551], &pointers[136], &pointers[915], &pointers[590], &pointers[430], &pointers[750], &pointers[819], &pointers[2], &pointers[114], &pointers[350], &pointers[532], &pointers[402], &pointers[763], &pointers[779], &pointers[633], &pointers[987], &pointers[465], &pointers[988], &pointers[625], &pointers[855], &pointers[478],
    &pointers[271], &pointers[977], &pointers[849], &pointers[739], &pointers[439], &pointers[732], &pointers[401], &pointers[786], &pointers[436], &pointers[293], &pointers[575], &pointers[116], &pointers[351], &pointers[267], &pointers[781], &pointers[328], &pointers[738], &pointers[934], &pointers[973], &pointers[980], &pointers[894], &pointers[297], &pointers[755], &pointers[445], &pointers[535], &pointers[44], &pointers[632], &pointers[705], &pointers[228], &pointers[198], &pointers[49], &pointers[59], &pointers[818], &pointers[595], &pointers[643], &pointers[92], &pointers[639], &pointers[939], &pointers[698], &pointers[671], &pointers[902], &pointers[233], &pointers[691], &pointers[835], &pointers[70], &pointers[794], &pointers[15], &pointers[555], &pointers[194], &pointers[761],
    &pointers[765], &pointers[957], &pointers[916], &pointers[521], &pointers[553], &pointers[450], &pointers[930], &pointers[156], &pointers[621], &pointers[229], &pointers[962], &pointers[87], &pointers[411], &pointers[134], &pointers[349], &pointers[793], &pointers[89], &pointers[451], &pointers[85], &pointers[241], &pointers[741], &pointers[170], &pointers[418], &pointers[507], &pointers[583], &pointers[766], &pointers[231], &pointers[380], &pointers[428], &pointers[79], &pointers[344], &pointers[842], &pointers[921], &pointers[378], &pointers[242], &pointers[848], &pointers[274], &pointers[246], &pointers[717], &pointers[404], &pointers[827], &pointers[154], &pointers[613], &pointers[280], &pointers[759], &pointers[466], &pointers[826], &pointers[554], &pointers[790], &pointers[356],
    &pointers[736], &pointers[950], &pointers[840], &pointers[390], &pointers[352], &pointers[624], &pointers[665], &pointers[984], &pointers[812], &pointers[813], &pointers[305], &pointers[670], &pointers[760], &pointers[24], &pointers[697], &pointers[463], &pointers[180], &pointers[799], &pointers[178], NULL, &pointers[268], &pointers[67], &pointers[929], &pointers[333], &pointers[88], &pointers[159], &pointers[248], &pointers[804], &pointers[29], &pointers[528], &pointers[850], &pointers[299], &pointers[906], &pointers[720], &pointers[891], &pointers[676], &pointers[420], &pointers[187], &pointers[498], &pointers[570], &pointers[833], &pointers[409], &pointers[900], &pointers[585], &pointers[147], &pointers[792], &pointers[513], &pointers[322], &pointers[245], &pointers[482],
    &pointers[5], &pointers[844], &pointers[145], &pointers[38], &pointers[711], &pointers[798], &pointers[23], &pointers[566], &pointers[782], &pointers[838], &pointers[874], &pointers[912], &pointers[405], &pointers[869], &pointers[493], &pointers[764], &pointers[830], &pointers[496], &pointers[364], &pointers[591], &pointers[703], &pointers[503], &pointers[204], &pointers[772], &pointers[190], &pointers[903], &pointers[491], &pointers[315], &pointers[188], &pointers[997], &pointers[635], &pointers[423], &pointers[845], &pointers[307], &pointers[688], &pointers[168], &pointers[192], &pointers[32], &pointers[480], &pointers[158], &pointers[309], &pointers[802], &pointers[556], &pointers[213], &pointers[606], &pointers[304], &pointers[598], &pointers[68], &pointers[700], &pointers[526],
    &pointers[321], &pointers[651], &pointers[919], &pointers[525], &pointers[419], &pointers[108], &pointers[46], &pointers[731], &pointers[871], &pointers[177], &pointers[972], &pointers[133], &pointers[471], &pointers[886], &pointers[839], &pointers[712], &pointers[357], &pointers[866], &pointers[815], &pointers[648], &pointers[425], &pointers[489], &pointers[152], &pointers[573], &pointers[805], &pointers[386], &pointers[571], &pointers[303], &pointers[200], &pointers[479], &pointers[454], &pointers[481], &pointers[831], &pointers[1], &pointers[60], &pointers[440], &pointers[593], &pointers[545], &pointers[975], &pointers[394], &pointers[557], &pointers[809], &pointers[634], &pointers[306], &pointers[163], &pointers[488], &pointers[97], &pointers[998], &pointers[273], &pointers[164],
    &pointers[410], &pointers[102], &pointers[967], &pointers[338], &pointers[52], &pointers[330], &pointers[84], &pointers[406], &pointers[66], &pointers[62], &pointers[568], &pointers[823], &pointers[536], &pointers[20], &pointers[19], &pointers[261], &pointers[33], &pointers[662], &pointers[287], &pointers[359], &pointers[118], &pointers[264], &pointers[237], &pointers[539], &pointers[110], &pointers[941], &pointers[985], &pointers[176], &pointers[235], &pointers[375], &pointers[693], &pointers[302], &pointers[920], &pointers[497], &pointers[191], &pointers[433], &pointers[824], &pointers[76], &pointers[494], &pointers[926], &pointers[443], &pointers[276], &pointers[710], &pointers[678], &pointers[94], &pointers[382], &pointers[577], &pointers[220], &pointers[699], &pointers[865],
    &pointers[904], &pointers[230], &pointers[640], &pointers[175], &pointers[298], &pointers[870], &pointers[130], &pointers[9], &pointers[437], &pointers[69], &pointers[694], &pointers[374], &pointers[398], &pointers[775], &pointers[48], &pointers[636], &pointers[132], &pointers[667], &pointers[167], &pointers[119], &pointers[883], &pointers[683], &pointers[858], &pointers[704], &pointers[353], &pointers[296], &pointers[656], &pointers[795], &pointers[282], &pointers[756], &pointers[148], &pointers[890], &pointers[888], &pointers[232], &pointers[722], &pointers[40], &pointers[561], &pointers[713], &pointers[582], &pointers[290], &pointers[510], &pointers[281], &pointers[389], &pointers[714], &pointers[395], &pointers[199], &pointers[166], &pointers[953], &pointers[272], &pointers[73],
    &pointers[829], &pointers[822], &pointers[275], &pointers[403], &pointers[279], &pointers[487], &pointers[343], &pointers[141], &pointers[878], &pointers[258], &pointers[339], &pointers[135], &pointers[908], &pointers[663], &pointers[516], &pointers[979], &pointers[637], &pointers[744], &pointers[106], &pointers[358], &pointers[363], &pointers[520], &pointers[600], &pointers[195], &pointers[696], &pointers[905], &pointers[626], &pointers[701], &pointers[562], &pointers[682], &pointers[728], &pointers[146], &pointers[337], &pointers[540], &pointers[876], &pointers[788], &pointers[881], &pointers[746], &pointers[257], &pointers[57], &pointers[969], &pointers[989], &pointers[925], &pointers[30], &pointers[686], &pointers[184], &pointers[574], &pointers[416], &pointers[149], &pointers[747],
    &pointers[269], &pointers[655], &pointers[379], &pointers[898], &pointers[715], &pointers[447], &pointers[572], &pointers[105], &pointers[702], &pointers[95], &pointers[165], &pointers[814], &pointers[515], &pointers[807], &pointers[629], &pointers[986], &pointers[787], &pointers[653], &pointers[417], &pointers[295], &pointers[724], &pointers[45], &pointers[753], &pointers[896], &pointers[723], &pointers[240], &pointers[26], &pointers[397], &pointers[948], &pointers[93], &pointers[935], &pointers[832], &pointers[873], &pointers[550], &pointers[206], &pointers[505], &pointers[502], &pointers[247], &pointers[982], &pointers[780], &pointers[172], &pointers[677], &pointers[897], &pointers[992], &pointers[331], &pointers[12], &pointers[587], &pointers[442], &pointers[254], &pointers[669],
    &pointers[951], &pointers[4], &pointers[680], &pointers[435], &pointers[767], &pointers[931], &pointers[458], &pointers[255], &pointers[211], &pointers[867], &pointers[438], &pointers[933], &pointers[3], &pointers[468], &pointers[776], &pointers[743], &pointers[547], &pointers[847], &pointers[601], &pointers[808], &pointers[219], &pointers[576], &pointers[313], &pointers[859], &pointers[752], &pointers[25], &pointers[372], &pointers[954], &pointers[630], &pointers[927], &pointers[265], &pointers[942], &pointers[825], &pointers[952], &pointers[707], &pointers[243], &pointers[174], &pointers[291], &pointers[262], &pointers[928], &pointers[740], &pointers[210], &pointers[153], &pointers[512], &pointers[266], &pointers[974], &pointers[424], &pointers[43], &pointers[882], &pointers[144],
    &pointers[652], &pointers[251], &pointers[129], &pointers[278], &pointers[34], &pointers[117], &pointers[856], &pointers[727], &pointers[990], &pointers[249], &pointers[354], &pointers[546], &pointers[995], &pointers[690], &pointers[329], &pointers[54], &pointers[183], &pointers[432], &pointers[945], &pointers[376], &pointers[128], &pointers[31], &pointers[884], &pointers[7], &pointers[270], &pointers[851], &pointers[523], &pointers[490], &pointers[806], &pointers[527], &pointers[36], &pointers[885], &pointers[791], &pointers[77], &pointers[495], &pointers[288], &pointers[155], &pointers[427], &pointers[778], &pointers[581], &pointers[366], &pointers[519], &pointers[846], &pointers[801], &pointers[260], &pointers[641], &pointers[963], &pointers[937], &pointers[91], &pointers[773],
    &pointers[742], &pointers[721], &pointers[277], &pointers[325], &pointers[751], &pointers[461], &pointers[317], &pointers[709], &pointers[966], &pointers[675], &pointers[501], &pointers[28], &pointers[602], &pointers[872], &pointers[324], &pointers[620], &pointers[672], &pointers[449], &pointers[189], &pointers[820], &pointers[559], &pointers[565], &pointers[181], &pointers[250], &pointers[615], &pointers[347], &pointers[619], &pointers[860], &pointers[887], &pointers[55], &pointers[138], &pointers[660], &pointers[599], &pointers[580], &pointers[301], &pointers[658], &pointers[853], &pointers[234], &pointers[50], &pointers[706], &pointers[875], &pointers[115], &pointers[361], &pointers[388], &pointers[544], &pointers[16], &pointers[769], &pointers[11], &pointers[326], &pointers[222],
    &pointers[578], &pointers[901], &pointers[589], &pointers[208], &pointers[341], &pointers[673], &pointers[978], &pointers[459], &pointers[668], &pointers[609], &pointers[368], &pointers[37], &pointers[797], &pointers[226], &pointers[294], &pointers[534], &pointers[647], &pointers[800], &pointers[367], &pointers[560], &pointers[332], &pointers[645], &pointers[983], &pointers[938], &pointers[252], &pointers[434], &pointers[470], &pointers[492], &pointers[475], &pointers[524], &pointers[209], &pointers[817], &pointers[821], &pointers[75], &pointers[958], &pointers[399], &pointers[499], &pointers[664], &pointers[500], &pointers[617], &pointers[224], &pointers[310], &pointers[976], &pointers[221], &pointers[649], &pointers[993], &pointers[207], &pointers[924], &pointers[123], &pointers[509],
    &pointers[955], &pointers[552], &pointers[109], &pointers[681], &pointers[8], &pointers[531], &pointers[777], &pointers[429], &pointers[970], &pointers[142], &pointers[362], &pointers[63], &pointers[21], &pointers[914], &pointers[334], &pointers[708], &pointers[549], &pointers[74], &pointers[81], &pointers[843], &pointers[286], &pointers[345], &pointers[179], &pointers[35], &pointers[71], &pointers[529], &pointers[959], &pointers[614], &pointers[391], &pointers[748], &pointers[726], &pointers[61], &pointers[964], &pointers[687], &pointers[383], &pointers[597], &pointers[373], &pointers[684], &pointers[618], &pointers[314], &pointers[474], &pointers[960], &pointers[112], &pointers[121], &pointers[666], &pointers[880], &pointers[197], &pointers[385], &pointers[472], &pointers[283],
    &pointers[730], &pointers[981], &pointers[592], &pointers[586], &pointers[841], &pointers[899], &pointers[857], &pointers[612], &pointers[323], &pointers[22], &pointers[733], &pointers[477], &pointers[758], &pointers[467], &pointers[239], &pointers[284], &pointers[414], &pointers[863], &pointers[111], &pointers[212], &pointers[910], &pointers[78], &pointers[17], &pointers[971], &pointers[567], &pointers[225], &pointers[879], &pointers[533], &pointers[193], &pointers[453], &pointers[716], &pointers[579], &pointers[877], &pointers[124], &pointers[412], &pointers[446], &pointers[96], &pointers[460], &pointers[151], &pointers[785], &pointers[253], &pointers[42], &pointers[644], &pointers[6], &pointers[171], &pointers[336], &pointers[685], &pointers[319], &pointers[695], &pointers[784],
    &pointers[932], &pointers[603], &pointers[484], &pointers[182], &pointers[541], &pointers[538], &pointers[511], &pointers[311], &pointers[185], &pointers[186], &pointers[41], &pointers[392], &pointers[852], &pointers[452], &pointers[196], &pointers[628], &pointers[393], &pointers[729], &pointers[944], &pointers[623], &pointers[58], &pointers[56], &pointers[485], &pointers[161], &pointers[285], &pointers[421], &pointers[864], &pointers[98], &pointers[122], &pointers[734], &pointers[160], &pointers[834], &pointers[548], &pointers[725], &pointers[407], &pointers[789], &pointers[371], &pointers[396], &pointers[53], &pointers[889], &pointers[922], &pointers[150], &pointers[139], &pointers[457], &pointers[289], &pointers[543], &pointers[355], &pointers[783], &pointers[646], &pointers[308],
    &pointers[895], &pointers[335], &pointers[456], &pointers[679], &pointers[605], &pointers[377], &pointers[907], &pointers[913], &pointers[127], &pointers[745], &pointers[348], &pointers[936], &pointers[994], &pointers[312], &pointers[659], &pointers[47], &pointers[862], &pointers[661], &pointers[816], &pointers[607], &pointers[968], &pointers[956], &pointers[627], &pointers[169], &pointers[558], &pointers[947], &pointers[205], &pointers[387], &pointers[911], &pointers[65], &pointers[999], &pointers[657], &pointers[14], &pointers[415], &pointers[868], &pointers[360], &pointers[718], &pointers[569], &pointers[961], &pointers[965], &pointers[564], &pointers[27], &pointers[10], &pointers[256], &pointers[202], &pointers[946], &pointers[223], &pointers[217], &pointers[828], &pointers[514]};

#endif

#ifdef POINTER_SIZE_1250
#ifdef FUNCTIONS_DATA_ON_CCM
  __attribute__((section(".ccmram")))
#endif
#ifdef FUNCTIONS_DATA_ON_FLASH
  const
#endif
   void *
#ifdef FUNCTIONS_DATA_ON_FLASH
  const
#endif
    pointers[1250] = {
    		&pointers[524], &pointers[359], &pointers[329], &pointers[259], &pointers[11], &pointers[690], &pointers[485], &pointers[693], &pointers[141], &pointers[528], &pointers[598], &pointers[429], &pointers[659], &pointers[1057], &pointers[938], &pointers[943], &pointers[916], &pointers[779], &pointers[452], &pointers[928], &pointers[671], &pointers[1226], &pointers[691], &pointers[468], &pointers[972], &pointers[125], &pointers[589], &pointers[444], &pointers[476], &pointers[1072], &pointers[312], &pointers[556], &pointers[253], &pointers[353], &pointers[191], &pointers[206], &pointers[1106], &pointers[564], &pointers[1125], &pointers[200], &pointers[326], &pointers[801], &pointers[807], &pointers[365], &pointers[391], &pointers[740], &pointers[776], &pointers[733], &pointers[999], &pointers[470],
    		&pointers[1081], &pointers[127], &pointers[811], &pointers[39], &pointers[433], &pointers[738], &pointers[900], &pointers[401], &pointers[142], &pointers[585], &pointers[954], &pointers[23], &pointers[804], &pointers[1033], &pointers[964], &pointers[1198], &pointers[487], &pointers[165], &pointers[1011], &pointers[638], &pointers[1236], &pointers[1191], &pointers[22], &pointers[1151], &pointers[426], &pointers[266], &pointers[887], &pointers[1235], &pointers[220], &pointers[686], &pointers[172], &pointers[411], &pointers[497], &pointers[273], &pointers[856], &pointers[284], &pointers[966], &pointers[1242], &pointers[65], &pointers[625], &pointers[1192], &pointers[169], &pointers[435], &pointers[475], &pointers[1021], &pointers[483], &pointers[371], &pointers[1139], &pointers[303], &pointers[760],
    		&pointers[166], &pointers[218], &pointers[549], &pointers[197], &pointers[815], &pointers[973], &pointers[1071], &pointers[322], &pointers[72], &pointers[151], &pointers[646], &pointers[274], &pointers[813], &pointers[1224], &pointers[730], &pointers[68], &pointers[491], &pointers[525], &pointers[1166], &pointers[1035], &pointers[809], &pointers[862], &pointers[17], &pointers[516], &pointers[775], &pointers[676], &pointers[225], &pointers[126], &pointers[519], &pointers[752], &pointers[729], &pointers[1214], &pointers[613], &pointers[430], &pointers[680], &pointers[20], &pointers[635], &pointers[624], &pointers[300], &pointers[1028], &pointers[847], &pointers[380], &pointers[715], &pointers[822], &pointers[1145], &pointers[955], &pointers[1141], &pointers[967], &pointers[285], &pointers[1239],
    		&pointers[1115], &pointers[461], &pointers[548], &pointers[941], &pointers[188], &pointers[583], &pointers[566], &pointers[515], &pointers[436], &pointers[739], &pointers[1112], &pointers[305], &pointers[854], &pointers[970], &pointers[1207], &pointers[622], &pointers[1093], &pointers[683], &pointers[35], &pointers[175], &pointers[490], &pointers[1213], &pointers[203], &pointers[1103], &pointers[1182], &pointers[150], &pointers[279], &pointers[405], &pointers[1172], &pointers[414], &pointers[214], &pointers[508], &pointers[1133], &pointers[1008], &pointers[135], &pointers[406], &pointers[104], &pointers[427], &pointers[626], &pointers[640], &pointers[424], &pointers[208], &pointers[454], &pointers[545], &pointers[92], &pointers[534], &pointers[15], &pointers[892], &pointers[344], &pointers[572],
    		&pointers[716], &pointers[910], &pointers[871], &pointers[44], &pointers[137], &pointers[1096], &pointers[26], &pointers[757], &pointers[201], &pointers[1176], &pointers[1169], &pointers[786], &pointers[808], &pointers[164], &pointers[767], &pointers[351], &pointers[1195], &pointers[144], NULL, &pointers[346], &pointers[18], &pointers[185], &pointers[753], &pointers[575], &pointers[1130], &pointers[952], &pointers[270], &pointers[650], &pointers[85], &pointers[119], &pointers[688], &pointers[773], &pointers[762], &pointers[1046], &pointers[790], &pointers[721], &pointers[1085], &pointers[81], &pointers[696], &pointers[918], &pointers[87], &pointers[381], &pointers[261], &pointers[503], &pointers[504], &pointers[400], &pointers[168], &pointers[180], &pointers[1134], &pointers[1225],
    		&pointers[486], &pointers[903], &pointers[1190], &pointers[1229], &pointers[1110], &pointers[1107], &pointers[325], &pointers[1014], &pointers[1092], &pointers[567], &pointers[271], &pointers[1054], &pointers[418], &pointers[310], &pointers[1073], &pointers[1211], &pointers[748], &pointers[759], &pointers[272], &pointers[451], &pointers[824], &pointers[4], &pointers[848], &pointers[570], &pointers[227], &pointers[865], &pointers[884], &pointers[1248], &pointers[1196], &pointers[709], &pointers[205], &pointers[250], &pointers[667], &pointers[32], &pointers[234], &pointers[912], &pointers[877], &pointers[59], &pointers[67], &pointers[875], &pointers[929], &pointers[1215], &pointers[16], &pointers[911], &pointers[147], &pointers[849], &pointers[932], &pointers[795], &pointers[766], &pointers[541],
    		&pointers[723], &pointers[231], &pointers[155], &pointers[559], &pointers[697], &pointers[634], &pointers[121], &pointers[844], &pointers[1109], &pointers[98], &pointers[889], &pointers[1220], &pointers[478], &pointers[1206], &pointers[53], &pointers[1168], &pointers[282], &pointers[254], &pointers[1217], &pointers[919], &pointers[1146], &pointers[533], &pointers[232], &pointers[702], &pointers[61], &pointers[249], &pointers[586], &pointers[148], &pointers[904], &pointers[194], &pointers[1152], &pointers[100], &pointers[765], &pointers[953], &pointers[1049], &pointers[1161], &pointers[1041], &pointers[91], &pointers[43], &pointers[551], &pointers[341], &pointers[593], &pointers[1084], &pointers[83], &pointers[960], &pointers[994], &pointers[890], &pointers[1070], &pointers[974], &pointers[980],
    		&pointers[799], &pointers[796], &pointers[1111], &pointers[378], &pointers[922], &pointers[458], &pointers[123], &pointers[958], &pointers[396], &pointers[416], &pointers[390], &pointers[117], &pointers[672], &pointers[720], &pointers[161], &pointers[1082], &pointers[24], &pointers[820], &pointers[1023], &pointers[183], &pointers[86], &pointers[403], &pointers[989], &pointers[798], &pointers[902], &pointers[681], &pointers[2], &pointers[1249], &pointers[324], &pointers[986], &pointers[498], &pointers[465], &pointers[1140], &pointers[1], &pointers[58], &pointers[440], &pointers[860], &pointers[657], &pointers[908], &pointers[394], &pointers[679], &pointers[756], &pointers[977], &pointers[343], &pointers[876], &pointers[488], &pointers[388], &pointers[74], &pointers[1042], &pointers[184],
    		&pointers[474], &pointers[328], &pointers[14], &pointers[244], &pointers[785], &pointers[674], &pointers[1164], &pointers[742], &pointers[1105], &pointers[639], &pointers[1048], &pointers[1209], &pointers[1079], &pointers[193], &pointers[356], &pointers[719], &pointers[975], &pointers[631], &pointers[457], &pointers[883], &pointers[1228], &pointers[174], &pointers[663], &pointers[375], &pointers[1135], &pointers[268], &pointers[477], &pointers[698], &pointers[868], &pointers[442], &pointers[1004], &pointers[741], &pointers[669], &pointers[215], &pointers[386], &pointers[761], &pointers[600], &pointers[1137], &pointers[610], &pointers[1153], &pointers[443], &pointers[278], &pointers[340], &pointers[1241], &pointers[836], &pointers[1200], &pointers[1143], &pointers[581], &pointers[1197], &pointers[370],
    		&pointers[223], &pointers[177], &pointers[1063], &pointers[437], &pointers[788], &pointers[252], &pointers[805], &pointers[314], &pointers[652], &pointers[732], &pointers[230], &pointers[979], &pointers[654], &pointers[198], &pointers[1202], &pointers[399], &pointers[714], &pointers[703], &pointers[818], &pointers[656], &pointers[1119], &pointers[869], &pointers[1160], &pointers[103], &pointers[1039], &pointers[289], &pointers[1009], &pointers[360], &pointers[527], &pointers[146], &pointers[666], &pointers[156], &pointers[1005], &pointers[56], &pointers[319], &pointers[263], &pointers[909], &pointers[705], &pointers[906], &pointers[204], &pointers[825], &pointers[834], &pointers[726], &pointers[357], &pointers[395], &pointers[90], &pointers[774], &pointers[120], &pointers[1144], &pointers[51],
    		&pointers[40], &pointers[797], &pointers[275], &pointers[95], &pointers[947], &pointers[780], &pointers[1126], &pointers[962], &pointers[1032], &pointers[258], &pointers[339], &pointers[107], &pointers[307], &pointers[934], &pointers[948], &pointers[792], &pointers[466], &pointers[149], &pointers[298], &pointers[931], &pointers[153], &pointers[413], &pointers[1203], &pointers[462], &pointers[735], &pointers[47], &pointers[577], &pointers[472], &pointers[1221], &pointers[112], &pointers[965], &pointers[661], &pointers[866], &pointers[981], &pointers[496], &pointers[616], &pointers[950], &pointers[1181], &pointers[192], &pointers[1044], &pointers[976], &pointers[134], &pointers[1230], &pointers[602], &pointers[31], &pointers[240], &pointers[574], &pointers[937], &pointers[781], &pointers[6],
    		&pointers[321], &pointers[158], &pointers[1188], &pointers[145], &pointers[30], &pointers[57], &pointers[935], &pointers[778], &pointers[1056], &pointers[1183], &pointers[173], &pointers[949], &pointers[597], &pointers[510], &pointers[629], &pointers[1117], &pointers[724], &pointers[467], &pointers[951], &pointers[853], &pointers[1129], &pointers[276], &pointers[277], &pointers[373], &pointers[281], &pointers[535], &pointers[995], &pointers[102], &pointers[658], &pointers[984], &pointers[162], &pointers[603], &pointers[49], &pointers[1189], &pointers[957], &pointers[843], &pointers[537], &pointers[684], &pointers[221], &pointers[237], &pointers[1001], &pointers[689], &pointers[1025], &pointers[643], &pointers[946], &pointers[1097], &pointers[812], &pointers[963], &pointers[507], &pointers[417],
    		&pointers[1043], &pointers[1113], &pointers[1149], &pointers[1245], &pointers[290], &pointers[210], &pointers[76], &pointers[588], &pointers[265], &pointers[267], &pointers[590], &pointers[392], &pointers[45], &pointers[101], &pointers[42], &pointers[895], &pointers[171], &pointers[235], &pointers[7], &pointers[1240], &pointers[555], &pointers[116], &pointers[157], &pointers[1131], &pointers[94], &pointers[78], &pointers[190], &pointers[985], &pointers[364], &pointers[309], &pointers[553], &pointers[755], &pointers[810], &pointers[248], &pointers[991], &pointers[728], &pointers[226], &pointers[455], &pointers[1147], &pointers[1237], &pointers[649], &pointers[1002], &pointers[896], &pointers[408], &pointers[152], &pointers[898], &pointers[1040], &pointers[379], &pointers[665], &pointers[628],
    		&pointers[372], &pointers[982], &pointers[131], &pointers[412], &pointers[787], &pointers[838], &pointers[617], &pointers[338], &pointers[552], &pointers[905], &pointers[93], &pointers[619], &pointers[114], &pointers[199], &pointers[800], &pointers[494], &pointers[1128], &pointers[998], &pointers[561], &pointers[1159], &pointers[34], &pointers[350], &pointers[384], &pointers[1178], &pointers[292], &pointers[926], &pointers[637], &pointers[936], &pointers[1010], &pointers[1080], &pointers[618], &pointers[269], &pointers[921], &pointers[469], &pointers[996], &pointers[425], &pointers[817], &pointers[1222], &pointers[143], &pointers[450], &pointers[337], &pointers[228], &pointers[1088], &pointers[136], &pointers[369], &pointers[518], &pointers[431], &pointers[565], &pointers[1051], &pointers[763],
    		&pointers[63], &pointers[211], &pointers[615], &pointers[956], &pointers[990], &pointers[513], &pointers[1050], &pointers[596], &pointers[837], &pointers[376], &pointers[432], &pointers[1234], &pointers[907], &pointers[1068], &pointers[579], &pointers[302], &pointers[521], &pointers[354], &pointers[245], &pointers[499], &pointers[297], &pointers[80], &pointers[859], &pointers[1037], &pointers[113], &pointers[446], &pointers[389], &pointers[1075], &pointers[627], &pointers[71], &pointers[138], &pointers[713], &pointers[335], &pointers[828], &pointers[879], &pointers[1086], &pointers[925], &pointers[202], &pointers[793], &pointers[293], &pointers[850], &pointers[1003], &pointers[978], &pointers[304], &pointers[1155], &pointers[576], &pointers[493], &pointers[1122], &pointers[653], &pointers[1076],
    		&pointers[771], &pointers[236], &pointers[873], &pointers[606], &pointers[692], &pointers[393], &pointers[675], &pointers[885], &pointers[382], &pointers[993], &pointers[840], &pointers[463], &pointers[961], &pointers[1165], &pointers[306], &pointers[544], &pointers[1077], &pointers[441], &pointers[754], &pointers[1212], &pointers[1187], &pointers[19], &pointers[1089], &pointers[1090], &pointers[1069], &pointers[181], &pointers[783], &pointers[1124], &pointers[878], &pointers[1083], &pointers[1114], &pointers[1015], &pointers[891], &pointers[1094], &pointers[608], &pointers[612], &pointers[867], &pointers[992], &pointers[1061], &pointers[434], &pointers[554], &pointers[707], &pointers[794], &pointers[229], &pointers[255], &pointers[872], &pointers[1243], &pointers[1064], &pointers[327], &pointers[587],
    		&pointers[484], &pointers[140], &pointers[128], &pointers[415], &pointers[262], &pointers[178], &pointers[355], &pointers[1059], &pointers[8], &pointers[99], &pointers[517], &pointers[1052], &pointers[456], &pointers[423], &pointers[54], &pointers[1007], &pointers[538], &pointers[806], &pointers[160], &pointers[526], &pointers[831], &pointers[1019], &pointers[495], &pointers[1038], &pointers[1148], &pointers[563], &pointers[1173], &pointers[301], &pointers[38], &pointers[256], &pointers[473], &pointers[1013], &pointers[66], &pointers[578], &pointers[132], &pointers[814], &pointers[573], &pointers[717], &pointers[33], &pointers[133], &pointers[316], &pointers[915], &pointers[917], &pointers[881], &pointers[70], &pointers[482], &pointers[711], &pointers[402], &pointers[219], &pointers[1029],
    		&pointers[1216], &pointers[1055], &pointers[1062], &pointers[677], &pointers[352], &pointers[1184], &pointers[251], &pointers[829], &pointers[750], &pointers[607], &pointers[13], &pointers[1101], &pointers[604], &pointers[1180], &pointers[1201], &pointers[159], &pointers[97], &pointers[5], &pointers[398], &pointers[826], &pointers[1156], &pointers[1022], &pointers[358], &pointers[428], &pointers[648], &pointers[239], &pointers[163], &pointers[1210], &pointers[945], &pointers[318], &pointers[296], &pointers[409], &pointers[419], &pointers[336], &pointers[923], &pointers[1208], &pointers[893], &pointers[187], &pointers[118], &pointers[1121], &pointers[764], &pointers[930], &pointers[933], &pointers[1078], &pointers[1157], &pointers[1247], &pointers[283], &pointers[3], &pointers[913], &pointers[447],
    		&pointers[52], &pointers[673], &pointers[1199], &pointers[642], &pointers[1171], &pointers[313], &pointers[1127], &pointers[1231], &pointers[367], &pointers[1179], &pointers[746], &pointers[1238], &pointers[260], &pointers[1186], &pointers[257], &pointers[678], &pointers[36], &pointers[983], &pointers[512], &pointers[170], &pointers[664], &pointers[217], &pointers[747], &pointers[1065], &pointers[901], &pointers[383], &pointers[725], &pointers[571], &pointers[96], &pointers[347], &pointers[410], &pointers[718], &pointers[1163], &pointers[73], &pointers[864], &pointers[55], &pointers[1017], &pointers[345], &pointers[546], &pointers[630], &pointers[182], &pointers[445], &pointers[1099], &pointers[1227], &pointers[363], &pointers[644], &pointers[870], &pointers[706], &pointers[222], &pointers[592],
    		&pointers[594], &pointers[12], &pointers[662], &pointers[1047], &pointers[511], &pointers[645], &pointers[704], &pointers[987], &pointers[845], &pointers[448], &pointers[501], &pointers[505], &pointers[768], &pointers[827], &pointers[207], &pointers[241], &pointers[464], &pointers[25], &pointers[361], &pointers[1031], &pointers[609], &pointers[195], &pointers[1162], &pointers[1246], &pointers[595], &pointers[286], &pointers[186], &pointers[489], &pointers[580], &pointers[1138], &pointers[374], &pointers[84], &pointers[562], &pointers[769], &pointers[1034], &pointers[647], &pointers[968], &pointers[1006], &pointers[37], &pointers[397], &pointers[196], &pointers[331], &pointers[701], &pointers[509], &pointers[1150], &pointers[543], &pointers[802], &pointers[77], &pointers[560], &pointers[1058],
    		&pointers[651], &pointers[874], &pointers[1170], &pointers[784], &pointers[833], &pointers[1193], &pointers[899], &pointers[1045], &pointers[558], &pointers[1036], &pointers[969], &pointers[685], &pointers[782], &pointers[823], &pointers[280], &pointers[1177], &pointers[1194], &pointers[287], &pointers[632], &pointers[655], &pointers[880], &pointers[841], &pointers[777], &pointers[694], &pointers[605], &pointers[731], &pointers[213], &pointers[997], &pointers[233], &pointers[882], &pointers[1204], &pointers[334], &pointers[1233], &pointers[421], &pointers[536], &pointers[682], &pointers[699], &pointers[154], &pointers[722], &pointers[332], &pointers[557], &pointers[10], &pointers[851], &pointers[50], &pointers[584], &pointers[734], &pointers[129], &pointers[246], &pointers[453], &pointers[939],
    		&pointers[727], &pointers[743], &pointers[62], &pointers[1027], &pointers[530], &pointers[1053], &pointers[1030], &pointers[460], &pointers[176], &pointers[1218], &pointers[481], &pointers[216], &pointers[1123], &pointers[789], &pointers[109], &pointers[64], &pointers[1012], &pointers[914], &pointers[708], &pointers[459], &pointers[1108], &pointers[500], &pointers[857], &pointers[520], &pointers[89], &pointers[514], &pointers[28], &pointers[636], &pointers[660], &pointers[349], &pointers[1024], &pointers[751], &pointers[167], &pointers[308], &pointers[1118], &pointers[88], &pointers[60], &pointers[523], &pointers[522], &pointers[224], &pointers[368], &pointers[9], &pointers[21], &pointers[832], &pointers[633], &pointers[110], &pointers[959], &pointers[1102], &pointers[438], &pointers[323],
    		&pointers[920], &pointers[532], &pointers[1185], &pointers[29], &pointers[330], &pointers[420], &pointers[1174], &pointers[542], &pointers[1000], &pointers[547], &pointers[179], &pointers[620], &pointers[333], &pointers[599], &pointers[209], &pointers[75], &pointers[1026], &pointers[189], &pointers[803], &pointers[846], &pointers[106], &pointers[568], &pointers[291], &pointers[988], &pointers[311], &pointers[858], &pointers[492], &pointers[737], &pointers[770], &pointers[835], &pointers[1091], &pointers[531], &pointers[377], &pointers[238], &pointers[48], &pointers[69], &pointers[670], &pointers[387], &pointers[687], &pointers[243], &pointers[1116], &pointers[611], &pointers[591], &pointers[614], &pointers[46], &pointers[944], &pointers[480], &pointers[1205], &pointers[242], &pointers[366],
    		&pointers[749], &pointers[1060], &pointers[758], &pointers[830], &pointers[582], &pointers[105], &pointers[819], &pointers[710], &pointers[247], &pointers[1120], &pointers[529], &pointers[863], &pointers[668], &pointers[940], &pointers[1136], &pointers[1016], &pointers[852], &pointers[422], &pointers[294], &pointers[736], &pointers[1167], &pointers[449], &pointers[641], &pointers[927], &pointers[82], &pointers[821], &pointers[1244], &pointers[139], &pointers[471], &pointers[1223], &pointers[295], &pointers[212], &pointers[861], &pointers[348], &pointers[601], &pointers[839], &pointers[385], &pointers[1158], &pointers[479], &pointers[695], &pointers[41], &pointers[745], &pointers[550], &pointers[439], &pointers[897], &pointers[971], &pointers[700], &pointers[894], &pointers[1232], &pointers[886],
    		&pointers[108], &pointers[115], &pointers[111], &pointers[288], &pointers[130], &pointers[569], &pointers[1067], &pointers[744], &pointers[1066], &pointers[320], &pointers[888], &pointers[124], &pointers[816], &pointers[855], &pointers[621], &pointers[407], &pointers[299], &pointers[1154], &pointers[79], &pointers[942], &pointers[712], &pointers[540], &pointers[1104], &pointers[502], &pointers[1175], &pointers[1018], &pointers[315], &pointers[1098], &pointers[404], &pointers[842], &pointers[539], &pointers[1100], &pointers[342], &pointers[317], &pointers[1142], &pointers[1132], &pointers[1095], &pointers[1219], &pointers[623], &pointers[791], &pointers[122], &pointers[506], &pointers[1074], &pointers[1020], &pointers[27], &pointers[772], &pointers[264], &pointers[362], &pointers[1087], &pointers[924]};

#endif

#ifdef POINTER_SIZE_1500
#ifdef FUNCTIONS_DATA_ON_CCM
  __attribute__((section(".ccmram")))
#endif
#ifdef FUNCTIONS_DATA_ON_FLASH
  const
#endif
   void *
#ifdef FUNCTIONS_DATA_ON_FLASH
  const
#endif
    pointers[1500] = {
    &pointers[1276], &pointers[438], &pointers[718], &pointers[1016], &pointers[11], &pointers[109], &pointers[517], &pointers[1221], &pointers[993], &pointers[1493], &pointers[1078], &pointers[429], &pointers[350], &pointers[1130], &pointers[564], &pointers[282], &pointers[594], &pointers[127], &pointers[1041], &pointers[928], &pointers[1160], &pointers[1180], &pointers[891], &pointers[690], &pointers[972], &pointers[522], &pointers[589], &pointers[444], &pointers[984], &pointers[453], &pointers[1181], &pointers[556], &pointers[153], &pointers[353], &pointers[259], &pointers[206], &pointers[1421], &pointers[861], &pointers[1125], &pointers[700], &pointers[1169], &pointers[654], &pointers[788], &pointers[126], &pointers[1298], &pointers[740], &pointers[459], &pointers[733], &pointers[534], &pointers[250],
    &pointers[262], &pointers[1045], &pointers[510], &pointers[683], &pointers[213], &pointers[951], &pointers[1027], &pointers[401], &pointers[48], &pointers[1381], &pointers[954], &pointers[1360], &pointers[50], &pointers[1179], &pointers[507], &pointers[1150], &pointers[487], &pointers[1168], &pointers[1011], &pointers[1413], &pointers[1166], &pointers[1428], &pointers[1245], &pointers[384], &pointers[851], &pointers[6], &pointers[887], &pointers[402], &pointers[748], &pointers[423], &pointers[1042], &pointers[633], &pointers[280], &pointers[498], &pointers[825], &pointers[1254], &pointers[966], &pointers[1199], &pointers[414], &pointers[1257], &pointers[1189], &pointers[935], &pointers[1404], &pointers[847], &pointers[204], &pointers[1038], &pointers[371], &pointers[734], &pointers[1006], &pointers[704],
    &pointers[166], &pointers[253], &pointers[1411], &pointers[197], &pointers[1200], &pointers[36], &pointers[455], &pointers[322], &pointers[792], NULL, &pointers[1116], &pointers[274], &pointers[1237], &pointers[1470], &pointers[267], &pointers[1308], &pointers[1478], &pointers[525], &pointers[1135], &pointers[1248], &pointers[760], &pointers[862], &pointers[979], &pointers[491], &pointers[619], &pointers[820], &pointers[636], &pointers[471], &pointers[519], &pointers[53], &pointers[729], &pointers[336], &pointers[860], &pointers[550], &pointers[680], &pointers[1113], &pointers[635], &pointers[1222], &pointers[437], &pointers[666], &pointers[741], &pointers[472], &pointers[1408], &pointers[867], &pointers[719], &pointers[405], &pointers[1171], &pointers[1072], &pointers[285], &pointers[256],
    &pointers[1457], &pointers[1388], &pointers[9], &pointers[1158], &pointers[710], &pointers[1100], &pointers[566], &pointers[822], &pointers[318], &pointers[670], &pointers[1338], &pointers[1284], &pointers[854], &pointers[73], &pointers[615], &pointers[546], &pointers[1231], &pointers[1372], &pointers[35], &pointers[631], &pointers[374], &pointers[181], &pointers[79], &pointers[903], &pointers[1419], &pointers[129], &pointers[646], &pointers[1468], &pointers[763], &pointers[516], &pointers[907], &pointers[569], &pointers[1151], &pointers[1008], &pointers[1453], &pointers[406], &pointers[1066], &pointers[427], &pointers[645], &pointers[640], &pointers[399], &pointers[208], &pointers[432], &pointers[545], &pointers[8], &pointers[605], &pointers[659], &pointers[159], &pointers[648], &pointers[1120],
    &pointers[184], &pointers[1167], &pointers[257], &pointers[1172], &pointers[1483], &pointers[1098], &pointers[732], &pointers[1097], &pointers[201], &pointers[1176], &pointers[77], &pointers[967], &pointers[1272], &pointers[1328], &pointers[1446], &pointers[749], &pointers[1184], &pointers[144], &pointers[1322], &pointers[346], &pointers[1427], &pointers[392], &pointers[1208], &pointers[677], &pointers[281], &pointers[51], &pointers[377], &pointers[650], &pointers[276], &pointers[768], &pointers[568], &pointers[773], &pointers[762], &pointers[1080], &pointers[1032], &pointers[349], &pointers[1290], &pointers[673], &pointers[177], &pointers[1057], &pointers[87], &pointers[297], &pointers[1252], &pointers[34], &pointers[504], &pointers[400], &pointers[1275], &pointers[180], &pointers[376], &pointers[1303],
    &pointers[909], &pointers[1250], &pointers[283], &pointers[251], &pointers[196], &pointers[815], &pointers[755], &pointers[506], &pointers[154], &pointers[616], &pointers[271], &pointers[113], &pointers[418], &pointers[946], &pointers[1139], &pointers[859], &pointers[950], &pointers[699], &pointers[1156], &pointers[39], &pointers[802], &pointers[4], &pointers[1292], &pointers[1433], &pointers[227], &pointers[110], &pointers[600], &pointers[1447], &pointers[1203], &pointers[239], &pointers[804], &pointers[500], &pointers[906], &pointers[844], &pointers[1495], &pointers[1266], &pointers[722], &pointers[623], &pointers[754], &pointers[667], &pointers[929], &pointers[1085], &pointers[1488], &pointers[339], &pointers[1196], &pointers[1497], &pointers[632], &pointers[342], &pointers[1486], &pointers[541],
    &pointers[123], &pointers[231], &pointers[497], &pointers[652], &pointers[697], &pointers[634], &pointers[121], &pointers[375], &pointers[1467], &pointers[1479], &pointers[1036], &pointers[716], &pointers[584], &pointers[676], &pointers[656], &pointers[872], &pointers[737], &pointers[586], &pointers[300], &pointers[387], &pointers[1379], &pointers[1136], &pointers[232], &pointers[563], &pointers[61], &pointers[1283], &pointers[533], &pointers[148], &pointers[1202], &pointers[1352], &pointers[1137], &pointers[100], &pointers[1244], &pointers[1355], &pointers[834], &pointers[899], &pointers[829], &pointers[554], &pointers[238], &pointers[980], &pointers[341], &pointers[593], &pointers[1106], &pointers[137], &pointers[838], &pointers[962], &pointers[890], &pointers[1070], &pointers[1362], &pointers[381],
    &pointers[1197], &pointers[782], &pointers[1293], &pointers[1412], &pointers[922], &pointers[1102], &pointers[974], &pointers[1], &pointers[1010], &pointers[97], &pointers[853], &pointers[117], &pointers[786], &pointers[856], &pointers[161], &pointers[424], &pointers[1190], &pointers[664], &pointers[1285], &pointers[183], &pointers[86], &pointers[1278], &pointers[989], &pointers[798], &pointers[40], &pointers[380], &pointers[1422], &pointers[793], &pointers[324], &pointers[986], &pointers[1344], &pointers[1124], &pointers[578], &pointers[1079], &pointers[1341], &pointers[363], &pointers[535], &pointers[158], &pointers[140], &pointers[570], &pointers[964], &pointers[808], &pointers[30], &pointers[1289], &pointers[1126], &pointers[921], &pointers[388], &pointers[1309], &pointers[1239], &pointers[896],
    &pointers[898], &pointers[328], &pointers[10], &pointers[244], &pointers[785], &pointers[772], &pointers[65], &pointers[742], &pointers[1105], &pointers[461], &pointers[585], &pointers[1049], &pointers[1214], &pointers[193], &pointers[312], &pointers[448], &pointers[1461], &pointers[582], &pointers[457], &pointers[488], &pointers[1474], &pointers[174], &pointers[917], &pointers[1439], &pointers[774], &pointers[268], &pointers[901], &pointers[698], &pointers[266], &pointers[442], &pointers[54], &pointers[1031], &pointers[32], &pointers[37], &pointers[1140], &pointers[1253], &pointers[560], &pointers[90], &pointers[482], &pointers[1012], &pointers[1387], &pointers[744], &pointers[340], &pointers[996], &pointers[836], &pointers[688], &pointers[1216], &pointers[1207], &pointers[675], &pointers[370],
    &pointers[655], &pointers[398], &pointers[540], &pointers[147], &pointers[1353], &pointers[1119], &pointers[551], &pointers[314], &pointers[939], &pointers[1256], &pointers[230], &pointers[701], &pointers[1059], &pointers[1043], &pointers[1443], &pointers[245], &pointers[1487], &pointers[915], &pointers[484], &pointers[1149], &pointers[1242], &pointers[145], &pointers[548], &pointers[103], &pointers[492], &pointers[462], &pointers[956], &pointers[473], &pointers[1317], &pointers[1499], &pointers[1485], &pointers[761], &pointers[308], &pointers[521], &pointers[870], &pointers[990], &pointers[199], &pointers[1217], &pointers[766], &pointers[936], &pointers[1063], &pointers[1376], &pointers[1112], &pointers[1094], &pointers[33], &pointers[1064], &pointers[531], &pointers[1305], &pointers[1280], &pointers[1291],
    &pointers[751], &pointers[927], &pointers[911], &pointers[1230], &pointers[947], &pointers[780], &pointers[1247], &pointers[871], &pointers[1215], &pointers[211], &pointers[1269], &pointers[1330], &pointers[1161], &pointers[934], &pointers[948], &pointers[1235], &pointers[965], &pointers[1358], &pointers[1466], &pointers[609], &pointers[435], &pointers[581], &pointers[709], &pointers[1255], &pointers[735], &pointers[47], &pointers[393], &pointers[1458], &pointers[644], &pointers[695], &pointers[1416], &pointers[800], &pointers[1131], &pointers[617], &pointers[791], &pointers[641], &pointers[884], &pointers[456], &pointers[1410], &pointers[450], &pointers[1306], &pointers[134], &pointers[892], &pointers[602], &pointers[31], &pointers[240], &pointers[485], &pointers[94], &pointers[175], &pointers[317],
    &pointers[84], &pointers[1472], &pointers[1324], &pointers[1001], &pointers[1452], &pointers[57], &pointers[1384], &pointers[835], &pointers[1056], &pointers[409], &pointers[756], &pointers[949], &pointers[597], &pointers[42], &pointers[1013], &pointers[1117], &pointers[261], &pointers[914], &pointers[994], &pointers[692], &pointers[938], &pointers[840], &pointers[152], &pointers[373], &pointers[118], &pointers[172], &pointers[995], &pointers[178], &pointers[1356], &pointers[1365], &pointers[162], &pointers[1243], &pointers[895], &pointers[344], &pointers[1310], &pointers[1175], &pointers[1183], &pointers[294], &pointers[1213], &pointers[237], &pointers[249], &pointers[1084], &pointers[1025], &pointers[643], &pointers[1444], &pointers[452], &pointers[1434], &pointers[963], &pointers[1492], &pointers[933],
    &pointers[897], &pointers[721], &pointers[1382], &pointers[44], &pointers[290], &pointers[1380], &pointers[76], &pointers[588], &pointers[1494], &pointers[465], &pointers[422], &pointers[669], &pointers[45], &pointers[78], &pointers[1145], &pointers[1073], &pointers[579], &pointers[1017], &pointers[1236], &pointers[351], &pointers[1133], &pointers[176], &pointers[1435], &pointers[1323], &pointers[441], &pointers[1021], &pointers[1409], &pointers[985], &pointers[364], &pointers[723], &pointers[1312], &pointers[1342], &pointers[131], &pointers[411], &pointers[991], &pointers[728], &pointers[279], &pointers[293], &pointers[868], &pointers[1464], &pointers[649], &pointers[1186], &pointers[603], &pointers[408], &pointers[739], &pointers[1003], &pointers[1061], &pointers[379], &pointers[466], &pointers[628],
    &pointers[372], &pointers[982], &pointers[992], &pointers[25], &pointers[630], &pointers[1096], &pointers[1333], &pointers[679], &pointers[1076], &pointers[433], &pointers[52], &pointers[1191], &pointers[624], &pointers[1343], &pointers[1383], &pointers[1152], &pointers[1314], &pointers[1347], &pointers[561], &pointers[874], &pointers[163], &pointers[296], &pointers[20], &pointers[81], &pointers[1018], &pointers[16], &pointers[575], &pointers[167], &pointers[315], &pointers[845], &pointers[618], &pointers[98], &pointers[1144], &pointers[1482], &pointers[192], &pointers[425], &pointers[1055], &pointers[520], &pointers[122], &pointers[608], &pointers[468], &pointers[246], &pointers[454], &pointers[136], &pointers[369], &pointers[248], &pointers[1262], &pointers[565], &pointers[1051], &pointers[833],
    &pointers[1087], &pointers[1111], &pointers[638], &pointers[894], &pointers[781], &pointers[513], &pointers[1050], &pointers[945], &pointers[837], &pointers[426], &pointers[596], &pointers[818], &pointers[169], &pointers[1287], &pointers[842], &pointers[1294], &pointers[529], &pointers[354], &pointers[831], &pointers[1378], &pointers[779], &pointers[265], &pointers[355], &pointers[358], &pointers[767], &pointers[1088], &pointers[674], &pointers[1075], &pointers[627], &pointers[1204], &pointers[1104], &pointers[713], &pointers[26], &pointers[828], &pointers[923], &pointers[1415], &pointers[865], &pointers[957], &pointers[1132], &pointers[106], &pointers[850], &pointers[852], &pointers[978], &pointers[304], &pointers[278], &pointers[1146], &pointers[843], &pointers[1350], &pointers[220], &pointers[658],
    &pointers[771], &pointers[539], &pointers[242], &pointers[606], &pointers[684], &pointers[478], &pointers[1044], &pointers[958], &pointers[185], &pointers[151], &pointers[1260], &pointers[1490], &pointers[961], &pointers[486], &pointers[306], &pointers[365], &pointers[2], &pointers[1354], &pointers[119], &pointers[1162], &pointers[880], &pointers[1185], &pointers[215], &pointers[1090], &pointers[15], &pointers[1414], &pointers[165], &pointers[1366], &pointers[787], &pointers[1471], &pointers[1114], &pointers[1258], &pointers[639], &pointers[1395], &pointers[1304], &pointers[612], &pointers[1026], &pointers[326], &pointers[85], &pointers[343], &pointers[975], &pointers[866], &pointers[1377], &pointers[813], &pointers[1052], &pointers[247], &pointers[1370], &pointers[1318], &pointers[327], &pointers[501],
    &pointers[335], &pointers[62], &pointers[321], &pointers[1405], &pointers[28], &pointers[1274], &pointers[157], &pointers[1211], &pointers[1364], &pointers[1320], &pointers[413], &pointers[943], &pointers[445], &pointers[920], &pointers[229], &pointers[1394], &pointers[544], &pointers[1074], &pointers[102], &pointers[1432], &pointers[715], &pointers[528], &pointers[203], &pointers[1157], &pointers[1426], &pointers[1077], &pointers[124], &pointers[301], &pointers[38], &pointers[334], &pointers[997], &pointers[571], &pointers[66], &pointers[1345], &pointers[225], &pointers[730], &pointers[573], &pointers[717], &pointers[146], &pointers[1155], &pointers[236], &pointers[217], &pointers[932], &pointers[583], &pointers[1484], &pointers[1449], &pointers[642], &pointers[198], &pointers[219], &pointers[59],
    &pointers[1460], &pointers[953], &pointers[367], &pointers[1219], &pointers[352], &pointers[1002], &pointers[241], &pointers[235], &pointers[750], &pointers[839], &pointers[142], &pointers[1101], &pointers[604], &pointers[1327], &pointers[1442], &pointers[881], &pointers[930], &pointers[495], &pointers[1418], &pointers[155], &pointers[160], &pointers[1329], &pointers[1368], &pointers[1385], &pointers[1399], &pointers[1441], &pointers[987], &pointers[913], &pointers[1279], &pointers[311], &pointers[885], &pointers[795], &pointers[988], &pointers[182], &pointers[1206], &pointers[1246], &pointers[70], &pointers[187], &pointers[1046], &pointers[794], &pointers[764], &pointers[467], &pointers[330], &pointers[1141], &pointers[451], &pointers[436], &pointers[665], &pointers[307], &pointers[474], &pointers[1224],
    &pointers[1188], &pointers[919], &pointers[1034], &pointers[490], &pointers[1407], &pointers[752], &pointers[738], &pointers[214], &pointers[80], &pointers[503], &pointers[613], &pointers[493], &pointers[260], &pointers[216], &pointers[12], &pointers[969], &pointers[882], &pointers[463], &pointers[114], &pointers[509], &pointers[412], &pointers[902], &pointers[747], &pointers[1261], &pointers[886], &pointers[135], &pointers[479], &pointers[475], &pointers[96], &pointers[1271], &pointers[390], &pointers[489], &pointers[591], &pointers[681], &pointers[1334], &pointers[360], &pointers[547], &pointers[275], &pointers[970], &pointers[316], &pointers[212], &pointers[1498], &pointers[1035], &pointers[1082], &pointers[391], &pointers[1060], &pointers[287], &pointers[706], &pointers[222], &pointers[592],
    &pointers[164], &pointers[1406], &pointers[417], &pointers[720], &pointers[511], &pointers[263], &pointers[888], &pointers[702], &pointers[292], &pointers[1134], &pointers[826], &pointers[505], &pointers[58], &pointers[827], &pointers[295], &pointers[1465], &pointers[464], &pointers[443], &pointers[361], &pointers[179], &pointers[925], &pointers[552], &pointers[1121], &pointers[1273], &pointers[577], &pointers[803], &pointers[1192], &pointers[1456], &pointers[580], &pointers[325], &pointers[1020], &pointers[1286], &pointers[562], &pointers[778], &pointers[1091], &pointers[647], &pointers[968], &pointers[790], &pointers[496], &pointers[397], &pointers[661], &pointers[331], &pointers[309], &pointers[614], &pointers[143], &pointers[543], &pointers[1476], &pointers[101], &pointers[421], &pointers[1361],
    &pointers[651], &pointers[1147], &pointers[120], &pointers[1386], &pointers[549], &pointers[863], &pointers[1138], &pointers[1223], &pointers[558], &pointers[973], &pointers[396], &pointers[685], &pointers[477], &pointers[1109], &pointers[1375], &pointers[63], &pointers[1339], &pointers[515], &pointers[944], &pointers[691], &pointers[678], &pointers[1210], &pointers[855], &pointers[694], &pointers[1259], &pointers[731], &pointers[976], &pointers[1187], &pointers[200], &pointers[819], &pointers[1445], &pointers[389], &pointers[611], &pointers[1014], &pointers[156], &pointers[712], &pointers[595], &pointers[810], &pointers[56], &pointers[430], &pointers[264], &pointers[553], &pointers[765], &pointers[1398], &pointers[1462], &pointers[1315], &pointers[879], &pointers[233], &pointers[526], &pointers[1451],
    &pointers[727], &pointers[1251], &pointers[254], &pointers[821], &pointers[128], &pointers[940], &pointers[1123], &pointers[3], &pointers[1337], &pointers[458], &pointers[1297], &pointers[812], &pointers[291], &pointers[877], &pointers[270], &pointers[889], &pointers[224], &pointers[878], &pointers[13], &pointers[657], &pointers[1357], &pointers[567], &pointers[672], &pointers[799], &pointers[21], &pointers[514], &pointers[1177], &pointers[714], &pointers[924], &pointers[1373], &pointers[469], &pointers[149], &pointers[1029], &pointers[1326], &pointers[252], &pointers[1459], &pointers[60], &pointers[1218], &pointers[116], &pointers[1402], &pointers[368], &pointers[1148], &pointers[671], &pointers[832], &pointers[1232], &pointers[112], &pointers[92], &pointers[1198], &pointers[383], &pointers[1005],
    &pointers[1110], &pointers[1249], &pointers[337], &pointers[757], &pointers[971], &pointers[1389], &pointers[629], &pointers[1220], &pointers[476], &pointers[518], &pointers[440], &pointers[759], &pointers[332], &pointers[29], &pointers[209], &pointers[88], &pointers[1299], &pointers[189], &pointers[682], &pointers[857], &pointers[1425], &pointers[1397], &pointers[362], &pointers[1030], &pointers[43], &pointers[858], &pointers[869], &pointers[1438], &pointers[1234], &pointers[981], &pointers[1401], &pointers[359], &pointers[91], &pointers[555], &pointers[191], &pointers[817], &pointers[133], &pointers[1095], &pointers[621], &pointers[1270], &pointers[386], &pointers[1173], &pointers[67], &pointers[610], &pointers[841], &pointers[916], &pointers[576], &pointers[434], &pointers[1281], &pointers[926],
    &pointers[959], &pointers[900], &pointers[1048], &pointers[955], &pointers[1348], &pointers[1103], &pointers[272], &pointers[95], &pointers[303], &pointers[1455], &pointers[1424], &pointers[186], &pointers[1129], &pointers[1423], &pointers[1264], &pointers[1182], &pointers[415], &pointers[502], &pointers[1349], &pointers[590], &pointers[1300], &pointers[1143], &pointers[1267], &pointers[538], &pointers[875], &pointers[1263], &pointers[1491], &pointers[1115], &pointers[89], &pointers[1473], &pointers[188], &pointers[876], &pointers[298], &pointers[1009], &pointers[139], &pointers[19], &pointers[1068], &pointers[660], &pointers[416], &pointers[777], &pointers[24], &pointers[1489], &pointers[1047], &pointers[1054], &pointers[323], &pointers[1296], &pointers[49], &pointers[202], &pointers[775], &pointers[1178],
    &pointers[302], &pointers[7], &pointers[904], &pointers[1015], &pointers[71], &pointers[1367], &pointers[1153], &pointers[1302], &pointers[753], &pointers[419], &pointers[537], &pointers[319], &pointers[849], &pointers[758], &pointers[1165], &pointers[410], &pointers[1053], &pointers[705], &pointers[1193], &pointers[960], &pointers[1069], &pointers[1454], &pointers[1396], &pointers[1429], &pointers[1331], &pointers[255], &pointers[783], &pointers[1437], &pointers[559], &pointers[625], &pointers[82], &pointers[1093], &pointers[357], &pointers[1226], &pointers[1431], &pointers[41], &pointers[1201], &pointers[626], &pointers[83], &pointers[104], &pointers[207], &pointers[1420], &pointers[846], &pointers[481], &pointers[816], &pointers[1024], &pointers[1351], &pointers[893], &pointers[1118], &pointers[572],
    &pointers[228], &pointers[743], &pointers[1480], &pointers[707], &pointers[286], &pointers[1089], &pointers[1436], &pointers[910], &pointers[171], &pointers[1229], &pointers[1469], &pointers[823], &pointers[601], &pointers[1099], &pointers[918], &pointers[912], &pointers[1265], &pointers[1371], &pointers[931], &pointers[801], &pointers[1022], &pointers[347], &pointers[908], &pointers[243], &pointers[333], &pointers[168], &pointers[524], &pointers[170], &pointers[403], &pointers[1363], &pointers[523], &pointers[499], &pointers[420], &pointers[234], &pointers[305], &pointers[1023], &pointers[494], &pointers[708], &pointers[1159], &pointers[1228], &pointers[1227], &pointers[1391], &pointers[848], &pointers[1058], &pointers[447], &pointers[320], &pointers[687], &pointers[470], &pointers[1071], &pointers[1440],
    &pointers[1313], &pointers[64], &pointers[1174], &pointers[428], &pointers[977], &pointers[807], &pointers[483], &pointers[1346], &pointers[68], &pointers[74], &pointers[1392], &pointers[223], &pointers[587], &pointers[542], &pointers[1107], &pointers[527], &pointers[746], &pointers[46], &pointers[269], &pointers[830], &pointers[1448], &pointers[952], &pointers[313], &pointers[1238], &pointers[99], &pointers[983], &pointers[532], &pointers[14], &pointers[905], &pointers[726], &pointers[107], &pointers[72], &pointers[1359], &pointers[1028], &pointers[864], &pointers[69], &pointers[1086], &pointers[620], &pointers[805], &pointers[1065], &pointers[108], &pointers[395], &pointers[1374], &pointers[1092], &pointers[1369], &pointers[536], &pointers[75], &pointers[770], &pointers[1033], &pointers[598],
    &pointers[1062], &pointers[1325], &pointers[811], &pointers[1340], &pointers[284], &pointers[1019], &pointers[194], &pointers[1000], &pointers[221], &pointers[277], &pointers[23], &pointers[1240], &pointers[1122], &pointers[1007], &pointers[711], &pointers[689], &pointers[574], &pointers[769], &pointers[141], &pointers[138], &pointers[382], &pointers[356], &pointers[809], &pointers[431], &pointers[508], &pointers[150], &pointers[5], &pointers[806], &pointers[385], &pointers[480], &pointers[1400], &pointers[1194], &pointers[366], &pointers[824], &pointers[394], &pointers[530], &pointers[724], &pointers[814], &pointers[686], &pointers[1282], &pointers[1163], &pointers[1403], &pointers[942], &pointers[1164], &pointers[205], &pointers[1288], &pointers[1316], &pointers[668], &pointers[557], &pointers[776],
    &pointers[696], &pointers[460], &pointers[1212], &pointers[1004], &pointers[653], &pointers[1128], &pointers[1307], &pointers[449], &pointers[105], &pointers[218], &pointers[796], &pointers[1268], &pointers[378], &pointers[736], &pointers[599], &pointers[1336], &pointers[607], &pointers[125], &pointers[1450], &pointers[1083], &pointers[190], &pointers[1475], &pointers[1301], &pointers[637], &pointers[937], &pointers[725], &pointers[1477], &pointers[18], &pointers[745], &pointers[1417], &pointers[439], &pointers[622], &pointers[1067], &pointers[1233], &pointers[1332], &pointers[1390], &pointers[1481], &pointers[1127], &pointers[195], &pointers[1321], &pointers[329], &pointers[999], &pointers[115], &pointers[111], &pointers[789], &pointers[130], &pointers[662], &pointers[512], &pointers[1277], &pointers[93],
    &pointers[345], &pointers[1295], &pointers[663], &pointers[1037], &pointers[693], &pointers[289], &pointers[273], &pointers[348], &pointers[22], &pointers[407], &pointers[299], &pointers[1081], &pointers[288], &pointers[1241], &pointers[1170], &pointers[1040], &pointers[338], &pointers[1430], &pointers[1393], &pointers[258], &pointers[1205], &pointers[1209], &pointers[210], &pointers[998], &pointers[1496], &pointers[17], &pointers[703], &pointers[873], &pointers[941], &pointers[1311], &pointers[1108], &pointers[173], &pointers[1319], &pointers[1463], &pointers[1225], &pointers[1335], &pointers[446], &pointers[1142], &pointers[784], &pointers[1039], &pointers[797], &pointers[27], &pointers[1195], &pointers[883], &pointers[55], &pointers[310], &pointers[404], &pointers[226], &pointers[1154], &pointers[132]};

#endif

#ifdef POINTER_SIZE_1750
#ifdef FUNCTIONS_DATA_ON_CCM
  __attribute__((section(".ccmram")))
#endif
#ifdef FUNCTIONS_DATA_ON_FLASH
  const
#endif
   void *
#ifdef FUNCTIONS_DATA_ON_FLASH
  const
#endif
    pointers[1750] = {
    &pointers[1276], &pointers[875], &pointers[718], &pointers[1621], &pointers[11], &pointers[1683], &pointers[517], &pointers[1221], &pointers[1230], &pointers[1388], &pointers[712], &pointers[429], &pointers[466], &pointers[1712], &pointers[302], &pointers[282], &pointers[171], &pointers[120], &pointers[237], &pointers[928], &pointers[1088], &pointers[1367], &pointers[257], &pointers[1745], &pointers[972], &pointers[675], &pointers[935], &pointers[1498], &pointers[984], &pointers[453], &pointers[1368], &pointers[46], &pointers[153], &pointers[254], &pointers[259], &pointers[1263], &pointers[1453], &pointers[849], &pointers[1125], &pointers[700], &pointers[1650], &pointers[654], &pointers[56], &pointers[920], &pointers[1082], &pointers[740], &pointers[1739], &pointers[1536], &pointers[458], &pointers[250],
    &pointers[1401], &pointers[263], &pointers[473], &pointers[683], &pointers[213], &pointers[951], &pointers[1244], &pointers[401], &pointers[422], &pointers[89], &pointers[1722], &pointers[1111], &pointers[208], &pointers[1728], &pointers[633], &pointers[584], &pointers[487], &pointers[201], &pointers[1011], &pointers[412], &pointers[240], &pointers[1665], &pointers[1729], &pointers[999], &pointers[851], &pointers[6], &pointers[887], &pointers[976], &pointers[399], &pointers[1106], &pointers[1120], &pointers[1327], &pointers[280], &pointers[1067], &pointers[1454], &pointers[1198], &pointers[966], &pointers[818], &pointers[286], &pointers[838], &pointers[1138], &pointers[1022], &pointers[217], &pointers[1094], &pointers[204], &pointers[1052], &pointers[1670], &pointers[937], &pointers[1072], &pointers[1748],
    &pointers[166], &pointers[253], &pointers[1026], &pointers[218], &pointers[1019], &pointers[677], &pointers[78], &pointers[322], &pointers[960], &pointers[215], &pointers[309], &pointers[274], &pointers[802], &pointers[603], &pointers[1158], &pointers[1308], &pointers[748], &pointers[525], &pointers[1170], &pointers[143], &pointers[491], &pointers[862], &pointers[342], &pointers[952], &pointers[99], &pointers[1642], &pointers[1361], &pointers[776], &pointers[42], &pointers[53], &pointers[729], &pointers[83], &pointers[1129], &pointers[550], &pointers[680], &pointers[589], &pointers[635], &pointers[1478], &pointers[437], &pointers[1575], &pointers[62], &pointers[472], &pointers[532], &pointers[1101], &pointers[179], &pointers[1147], &pointers[768], &pointers[1487], &pointers[285], &pointers[1311],
    &pointers[1313], &pointers[1616], &pointers[844], &pointers[1014], &pointers[1436], &pointers[440], &pointers[377], &pointers[564], &pointers[681], &pointers[467], &pointers[682], &pointers[1284], &pointers[1374], &pointers[1242], &pointers[730], &pointers[546], &pointers[1231], &pointers[917], &pointers[599], &pointers[716], &pointers[1547], &pointers[1553], &pointers[1007], &pointers[1696], &pointers[1663], &pointers[129], &pointers[646], &pointers[994], &pointers[332], &pointers[554], &pointers[33], &pointers[1352], &pointers[945], &pointers[1008], &pointers[518], &pointers[1074], &pointers[197], &pointers[427], &pointers[645], &pointers[640], &pointers[1044], &pointers[703], &pointers[432], &pointers[1122], &pointers[480], &pointers[605], &pointers[433], &pointers[1226], &pointers[1066], &pointers[1329],
    &pointers[652], &pointers[765], &pointers[357], &pointers[760], &pointers[1040], &pointers[393], &pointers[311], &pointers[1272], &pointers[157], &pointers[1176], &pointers[1494], &pointers[1175], &pointers[1479], &pointers[866], &pointers[1365], &pointers[1194], &pointers[1485], &pointers[1720], &pointers[1541], &pointers[346], &pointers[44], &pointers[1118], &pointers[1208], &pointers[1318], &pointers[644], &pointers[1496], &pointers[569], &pointers[650], &pointers[276], &pointers[177], &pointers[568], &pointers[773], &pointers[762], &pointers[1107], &pointers[1579], &pointers[631], &pointers[1549], &pointers[1680], &pointers[172], &pointers[664], &pointers[884], &pointers[1286], &pointers[665], &pointers[34], &pointers[1548], &pointers[502], &pointers[1706], &pointers[1597], &pointers[376], &pointers[1295],
    &pointers[1274], &pointers[1449], &pointers[283], &pointers[251], &pointers[1297], &pointers[50], &pointers[1038], &pointers[1268], &pointers[229], &pointers[616], &pointers[271], &pointers[1180], &pointers[184], &pointers[154], &pointers[410], &pointers[859], &pointers[459], &pointers[1428], &pointers[1499], &pointers[39], &pointers[1472], &pointers[4], &pointers[1292], &pointers[1247], &pointers[227], &pointers[1172], &pointers[600], &pointers[1061], &pointers[1143], &pointers[345], &pointers[804], &pointers[1119], &pointers[1154], &pointers[63], &pointers[1557], &pointers[1266], &pointers[808], &pointers[1515], &pointers[996], &pointers[667], &pointers[929], &pointers[1085], &pointers[1732], &pointers[339], &pointers[1387], &pointers[1552], &pointers[114], &pointers[387], &pointers[1723], &pointers[541],
    &pointers[390], &pointers[231], &pointers[211], &pointers[577], &pointers[697], &pointers[1477], &pointers[121], &pointers[375], &pointers[1078], &pointers[1254], &pointers[1165], &pointers[942], &pointers[1674], &pointers[896], &pointers[174], &pointers[872], &pointers[343], &pointers[586], &pointers[596], &pointers[1168], &pointers[242], &pointers[1281], &pointers[232], &pointers[658], &pointers[1608], &pointers[889], &pointers[1390], &pointers[1561], &pointers[1202], &pointers[1188], &pointers[396], &pointers[1475], &pointers[155], &pointers[519], &pointers[609], &pointers[69], &pointers[863], &pointers[1413], &pointers[1471], &pointers[980], &pointers[341], &pointers[593], &pointers[325], &pointers[1529], &pointers[156], &pointers[509], &pointers[890], &pointers[1070], &pointers[93], &pointers[1299],
    &pointers[1197], &pointers[1530], &pointers[1264], NULL, &pointers[1410], &pointers[435], &pointers[349], &pointers[1164], &pointers[957], &pointers[782], &pointers[428], &pointers[117], &pointers[923], &pointers[1599], &pointers[161], &pointers[626], &pointers[1190], &pointers[1073], &pointers[1285], &pointers[183], &pointers[1293], &pointers[1278], &pointers[989], &pointers[1569], &pointers[855], &pointers[380], &pointers[1657], &pointers[701], &pointers[959], &pointers[986], &pointers[1565], &pointers[92], &pointers[415], &pointers[907], &pointers[1035], &pointers[1300], &pointers[479], &pointers[879], &pointers[1532], &pointers[1645], &pointers[1605], &pointers[1191], &pointers[30], &pointers[1325], &pointers[235], &pointers[109], &pointers[1584], &pointers[1528], &pointers[1692], &pointers[1277],
    &pointers[388], &pointers[328], &pointers[1039], &pointers[244], &pointers[785], &pointers[1306], &pointers[158], &pointers[742], &pointers[1105], &pointers[461], &pointers[1718], &pointers[358], &pointers[52], &pointers[321], &pointers[455], &pointers[1456], &pointers[220], &pointers[970], &pointers[1563], &pointers[488], &pointers[1717], &pointers[1414], &pointers[1676], &pointers[795], &pointers[1021], &pointers[268], &pointers[374], &pointers[698], &pointers[1235], &pointers[1585], &pointers[702], &pointers[1173], &pointers[32], &pointers[659], &pointers[287], &pointers[1151], &pointers[738], &pointers[90], &pointers[275], &pointers[1594], &pointers[36], &pointers[1447], &pointers[340], &pointers[921], &pointers[836], &pointers[1053], &pointers[37], &pointers[881], &pointers[1560], &pointers[1604],
    &pointers[496], &pointers[1015], &pointers[540], &pointers[147], &pointers[979], &pointers[857], &pointers[1513], &pointers[238], &pointers[1097], &pointers[916], &pointers[913], &pointers[1160], &pointers[527], &pointers[1018], &pointers[1682], &pointers[324], &pointers[1434], &pointers[874], &pointers[1065], &pointers[1455], &pointers[1445], &pointers[856], &pointers[548], &pointers[1622], &pointers[1491], &pointers[933], &pointers[1177], &pointers[899], &pointers[385], &pointers[173], &pointers[394], &pointers[761], &pointers[594], &pointers[521], &pointers[585], &pointers[1328], &pointers[1006], &pointers[1517], &pointers[766], &pointers[799], &pointers[1349], &pointers[852], &pointers[335], &pointers[360], &pointers[722], &pointers[1076], &pointers[1747], &pointers[142], &pointers[58], &pointers[1503],
    &pointers[1342], &pointers[277], &pointers[391], &pointers[1402], &pointers[947], &pointers[780], &pointers[575], &pointers[411], &pointers[1089], &pointers[506], &pointers[1669], &pointers[1330], &pointers[1189], &pointers[934], &pointers[1589], &pointers[1432], &pointers[1643], &pointers[1134], &pointers[536], &pointers[653], &pointers[462], &pointers[581], &pointers[1386], &pointers[1304], &pointers[1520], &pointers[47], &pointers[1270], &pointers[1460], &pointers[8], &pointers[1465], &pointers[95], &pointers[402], &pointers[1149], &pointers[617], &pointers[43], &pointers[212], &pointers[451], &pointers[247], &pointers[323], &pointers[520], &pointers[1525], &pointers[134], &pointers[1399], &pointers[1689], &pointers[621], &pointers[522], &pointers[485], &pointers[1743], &pointers[175], &pointers[317],
    &pointers[84], &pointers[1508], &pointers[164], &pointers[578], &pointers[1229], &pointers[57], &pointers[1379], &pointers[478], &pointers[1056], &pointers[1363], &pointers[417], &pointers[949], &pointers[597], &pointers[926], &pointers[1049], &pointers[1439], &pointers[794], &pointers[1612], &pointers[119], &pointers[1238], &pointers[1298], &pointers[840], &pointers[1162], &pointers[373], &pointers[118], &pointers[1104], &pointers[995], &pointers[1115], &pointers[690], &pointers[1588], &pointers[1417], &pointers[1059], &pointers[1615], &pointers[128], &pointers[1083], &pointers[88], &pointers[1340], &pointers[294], &pointers[1161], &pointers[29], &pointers[113], &pointers[1716], &pointers[1025], &pointers[643], &pointers[1255], &pointers[1137], &pointers[51], &pointers[963], &pointers[1324], &pointers[1667],
    &pointers[897], &pointers[721], &pointers[1610], &pointers[418], &pointers[290], &pointers[1607], &pointers[76], &pointers[888], &pointers[1740], &pointers[105], &pointers[725], &pointers[1461], &pointers[45], &pointers[145], &pointers[261], &pointers[469], &pointers[579], &pointers[1017], &pointers[1675], &pointers[613], &pointers[1638], &pointers[176], &pointers[1673], &pointers[10], &pointers[465], &pointers[1012], &pointers[1425], &pointers[985], &pointers[364], &pointers[330], &pointers[1531], &pointers[810], &pointers[938], &pointers[507], &pointers[991], &pointers[728], &pointers[190], &pointers[293], &pointers[1730], &pointers[378], &pointers[1405], &pointers[1225], &pointers[656], &pointers[408], &pointers[454], &pointers[1003], &pointers[1630], &pointers[379], &pointers[1559], &pointers[628],
    &pointers[372], &pointers[982], &pointers[1033], &pointers[1463], &pointers[630], &pointers[443], &pointers[560], &pointers[673], &pointers[684], &pointers[1661], &pointers[1646], &pointers[85], &pointers[356], &pointers[1296], &pointers[704], &pointers[1464], &pointers[751], &pointers[1290], &pointers[1376], &pointers[542], &pointers[1132], &pointers[350], &pointers[801], &pointers[582], &pointers[1037], &pointers[755], &pointers[806], &pointers[861], &pointers[1102], &pointers[971], &pointers[618], &pointers[1312], &pointers[754], &pointers[1566], &pointers[246], &pointers[425], &pointers[1043], &pointers[1110], &pointers[400], &pointers[1484], &pointers[1196], &pointers[793], &pointers[1069], &pointers[136], &pointers[369], &pointers[1741], &pointers[1466], &pointers[565], &pointers[1051], &pointers[1700],
    &pointers[1258], &pointers[108], &pointers[54], &pointers[1435], &pointers[1057], &pointers[513], &pointers[1050], &pointers[1686], &pointers[837], &pointers[1139], &pointers[925], &pointers[239], &pointers[1571], &pointers[1721], &pointers[1], &pointers[791], &pointers[763], &pointers[354], &pointers[831], &pointers[438], &pointers[779], &pointers[265], &pointers[363], &pointers[1027], &pointers[767], &pointers[300], &pointers[482], &pointers[1075], &pointers[627], &pointers[1423], &pointers[1581], &pointers[713], &pointers[424], &pointers[828], &pointers[607], &pointers[1629], &pointers[1366], &pointers[1234], &pointers[723], &pointers[553], &pointers[850], &pointers[1473], &pointers[978], &pointers[304], &pointers[895], &pointers[1146], &pointers[639], &pointers[1572], &pointers[886], &pointers[1341],
    &pointers[771], &pointers[281], &pointers[1595], &pointers[606], &pointers[1644], &pointers[572], &pointers[648], &pointers[958], &pointers[843], &pointers[1002], &pointers[1079], &pointers[1551], &pointers[961], &pointers[807], &pointers[306], &pointers[1064], &pointers[2], &pointers[1576], &pointers[1287], &pointers[1725], &pointers[880], &pointers[1185], &pointers[1302], &pointers[1090], &pointers[1034], &pointers[1338], &pointers[1232], &pointers[1426], &pointers[787], &pointers[1357], &pointers[1114], &pointers[845], &pointers[911], &pointers[1625], &pointers[1397], &pointers[612], &pointers[1481], &pointers[326], &pointers[110], &pointers[1468], &pointers[975], &pointers[775], &pointers[1419], &pointers[1691], &pointers[860], &pointers[1540], &pointers[1620], &pointers[1537], &pointers[327], &pointers[1626],
    &pointers[1713], &pointers[20], &pointers[567], &pointers[1637], &pointers[28], &pointers[248], &pointers[666], &pointers[1708], &pointers[1406], &pointers[1243], &pointers[1055], &pointers[1522], &pointers[497], &pointers[676], &pointers[124], &pointers[1392], &pointers[1273], &pointers[1245], &pointers[439], &pointers[1337], &pointers[475], &pointers[91], &pointers[746], &pointers[1375], &pointers[351], &pointers[386], &pointers[245], &pointers[301], &pointers[38], &pointers[1664], &pointers[997], &pointers[571], &pointers[66], &pointers[103], &pointers[430], &pointers[914], &pointers[573], &pointers[717], &pointers[853], &pointers[1155], &pointers[236], &pointers[348], &pointers[206], &pointers[214], &pointers[196], &pointers[59], &pointers[48], &pointers[230], &pointers[219], &pointers[25],
    &pointers[1699], &pointers[953], &pointers[789], &pointers[160], &pointers[352], &pointers[1344], &pointers[1666], &pointers[641], &pointers[750], &pointers[839], &pointers[132], &pointers[812], &pointers[604], &pointers[699], &pointers[1681], &pointers[1655], &pointers[1396], &pointers[772], &pointers[1734], &pointers[1542], &pointers[523], &pointers[769], &pointers[1200], &pointers[737], &pointers[1550], &pointers[1543], &pointers[1219], &pointers[1408], &pointers[1178], &pointers[1166], &pointers[885], &pointers[1400], &pointers[1458], &pointers[792], &pointers[823], &pointers[1742], &pointers[297], &pointers[187], &pointers[1592], &pointers[234], &pointers[764], &pointers[500], &pointers[1697], &pointers[1393], &pointers[758], &pointers[1654], &pointers[638], &pointers[307], &pointers[969], &pointers[662],
    &pointers[1381], &pointers[225], &pointers[498], &pointers[1518], &pointers[1279], &pointers[707], &pointers[192], &pointers[1250], &pointers[1283], &pointers[503], &pointers[122], &pointers[3], &pointers[260], &pointers[847], &pointers[1519], &pointers[711], &pointers[744], &pointers[131], &pointers[1554], &pointers[903], &pointers[931], &pointers[1116], &pointers[747], &pointers[5], &pointers[1071], &pointers[687], &pointers[1046], &pointers[1163], &pointers[96], &pointers[1271], &pointers[492], &pointers[1424], &pointers[1359], &pointers[1562], &pointers[1334], &pointers[1370], &pointers[967], &pointers[1476], &pointers[1719], &pointers[1653], &pointers[249], &pointers[1355], &pointers[529], &pointers[1319], &pointers[1220], &pointers[1068], &pointers[205], &pointers[706], &pointers[222], &pointers[592],
    &pointers[583], &pointers[1486], &pointers[355], &pointers[720], &pointers[1590], &pointers[894], &pointers[1651], &pointers[826], &pointers[292], &pointers[741], &pointers[1206], &pointers[505], &pointers[312], &pointers[827], &pointers[1199], &pointers[35], &pointers[464], &pointers[320], &pointers[1444], &pointers[477], &pointers[1707], &pointers[1603], &pointers[1121], &pointers[1480], &pointers[1636], &pointers[803], &pointers[623], &pointers[1695], &pointers[580], &pointers[484], &pointers[1649], &pointers[266], &pointers[562], &pointers[778], &pointers[1091], &pointers[1427], &pointers[968], &pointers[790], &pointers[1586], &pointers[397], &pointers[1005], &pointers[331], &pointers[1100], &pointers[736], &pointers[1351], &pointers[543], &pointers[1715], &pointers[101], &pointers[1212], &pointers[1153],
    &pointers[1411], &pointers[151], &pointers[619], &pointers[1371], &pointers[549], &pointers[557], &pointers[1606], &pointers[434], &pointers[558], &pointers[1246], &pointers[365], &pointers[685], &pointers[526], &pointers[1512], &pointers[303], &pointers[1113], &pointers[474], &pointers[515], &pointers[456], &pointers[814], &pointers[678], &pointers[15], &pointers[308], &pointers[694], &pointers[661], &pointers[1326], &pointers[1746], &pointers[998], &pointers[490], &pointers[749], &pointers[1684], &pointers[140], &pointers[1310], &pointers[1343], &pointers[1182], &pointers[470], &pointers[595], &pointers[1184], &pointers[1195], &pointers[1398], &pointers[1269], &pointers[1294], &pointers[825], &pointers[846], &pointers[23], &pointers[981], &pointers[1241], &pointers[18], &pointers[869], &pointers[405],
    &pointers[727], &pointers[1251], &pointers[824], &pointers[910], &pointers[210], &pointers[1647], &pointers[1123], &pointers[338], &pointers[1364], &pointers[1440], &pointers[1301], &pointers[1564], &pointers[291], &pointers[1459], &pointers[384], &pointers[216], &pointers[537], &pointers[1140], &pointers[1077], &pointers[1577], &pointers[1555], &pointers[1092], &pointers[544], &pointers[168], &pointers[1136], &pointers[514], &pointers[1181], &pointers[691], &pointers[955], &pointers[1333], &pointers[191], &pointers[924], &pointers[939], &pointers[642], &pointers[381], &pointers[1698], &pointers[60], &pointers[61], &pointers[1345], &pointers[1029], &pointers[368], &pointers[1148], &pointers[941], &pointers[832], &pointers[1063], &pointers[493], &pointers[1239], &pointers[1416], &pointers[516], &pointers[116],
    &pointers[494], &pointers[495], &pointers[315], &pointers[757], &pointers[1701], &pointers[1389], &pointers[423], &pointers[31], &pointers[460], &pointers[1591], &pointers[1001], &pointers[788], &pointers[547], &pointers[463], &pointers[209], &pointers[1409], &pointers[974], &pointers[189], &pointers[392], &pointers[1321], &pointers[1010], &pointers[1628], &pointers[486], &pointers[1030], &pointers[528], &pointers[1614], &pointers[816], &pointers[1257], &pointers[65], &pointers[159], &pointers[483], &pointers[123], &pointers[1362], &pointers[1305], &pointers[1580], &pointers[87], &pointers[993], &pointers[1511], &pointers[1378], &pointers[1429], &pointers[809], &pointers[1084], &pointers[988], &pointers[150], &pointers[1538], &pointers[834], &pointers[1443], &pointers[1509], &pointers[1490], &pointers[1714],
    &pointers[262], &pointers[398], &pointers[1385], &pointers[1372], &pointers[241], &pointers[1316], &pointers[272], &pointers[270], &pointers[686], &pointers[1260], &pointers[710], &pointers[1142], &pointers[16], &pointers[805], &pointers[1442], &pointers[1036], &pointers[1623], &pointers[79], &pointers[144], &pointers[1671], &pointers[1289], &pointers[202], &pointers[1587], &pointers[1391], &pointers[1596], &pointers[624], &pointers[1735], &pointers[1346], &pointers[1737], &pointers[987], &pointers[73], &pointers[1157], &pointers[1403], &pointers[534], &pointers[12], &pointers[19], &pointers[1124], &pointers[431], &pointers[314], &pointers[1222], &pointers[24], &pointers[97], &pointers[510], &pointers[1348], &pointers[1315], &pointers[489], &pointers[1141], &pointers[1252], &pointers[1710], &pointers[877],
    &pointers[1109], &pointers[7], &pointers[904], &pointers[1493], &pointers[1360], &pointers[1497], &pointers[932], &pointers[1045], &pointers[1533], &pointers[419], &pointers[1567], &pointers[1353], &pointers[1702], &pointers[70], &pointers[842], &pointers[1641], &pointers[655], &pointers[705], &pointers[1524], &pointers[1179], &pointers[883], &pointers[1693], &pointers[1358], &pointers[1404], &pointers[819], &pointers[615], &pointers[1024], &pointers[786], &pointers[180], &pointers[1395], &pointers[416], &pointers[1093], &pointers[660], &pointers[178], &pointers[1307], &pointers[882], &pointers[1201], &pointers[243], &pointers[588], &pointers[337], &pointers[1099], &pointers[1382], &pointers[1213], &pointers[538], &pointers[426], &pointers[21], &pointers[973], &pointers[1617], &pointers[1135], &pointers[163],
    &pointers[1187], &pointers[743], &pointers[1016], &pointers[1711], &pointers[457], &pointers[715], &pointers[336], &pointers[1677], &pointers[1174], &pointers[1624], &pointers[1694], &pointers[830], &pointers[1339], &pointers[556], &pointers[1505], &pointers[912], &pointers[1265], &pointers[1736], &pointers[873], &pointers[1703], &pointers[1501], &pointers[347], &pointers[367], &pointers[1527], &pointers[909], &pointers[1640], &pointers[524], &pointers[1042], &pointers[403], &pointers[1332], &pointers[1218], &pointers[133], &pointers[420], &pointers[1223], &pointers[305], &pointers[1023], &pointers[821], &pointers[962], &pointers[258], &pointers[1317], &pointers[1568], &pointers[1407], &pointers[848], &pointers[86], &pointers[1514], &pointers[1749], &pointers[1087], &pointers[1556], &pointers[918], &pointers[1262],
    &pointers[1470], &pointers[441], &pointers[26], &pointers[1688], &pointers[1013], &pointers[555], &pointers[1267], &pointers[224], &pointers[68], &pointers[1431], &pointers[1437], &pointers[471], &pointers[1131], &pointers[1648], &pointers[878], &pointers[905], &pointers[1103], &pointers[817], &pointers[1152], &pointers[298], &pointers[708], &pointers[815], &pointers[820], &pointers[636], &pointers[739], &pointers[1521], &pointers[1380], &pointers[1660], &pointers[1203], &pointers[1574], &pointers[107], &pointers[366], &pointers[1639], &pointers[1377], &pointers[864], &pointers[663], &pointers[1086], &pointers[353], &pointers[734], &pointers[1096], &pointers[1009], &pointers[1611], &pointers[1259], &pointers[671], &pointers[1492], &pointers[719], &pointers[1214], &pointers[80], &pointers[1659], &pointers[185],
    &pointers[1457], &pointers[223], &pointers[709], &pointers[1704], &pointers[1031], &pointers[1506], &pointers[1421], &pointers[1253], &pointers[956], &pointers[563], &pointers[71], &pointers[901], &pointers[135], &pointers[1488], &pointers[1558], &pointers[530], &pointers[759], &pointers[188], &pointers[876], &pointers[576], &pointers[1709], &pointers[724], &pointers[279], &pointers[1546], &pointers[854], &pointers[1186], &pointers[561], &pointers[1288], &pointers[777], &pointers[1394], &pointers[731], &pointers[170], &pointers[67], &pointers[256], &pointers[1535], &pointers[900], &pointers[531], &pointers[49], &pointers[1452], &pointers[1282], &pointers[1583], &pointers[389], &pointers[72], &pointers[1227], &pointers[1418], &pointers[1731], &pointers[992], &pointers[977], &pointers[1687], &pointers[1534],
    &pointers[1047], &pointers[1126], &pointers[82], &pointers[1112], &pointers[535], &pointers[649], &pointers[1504], &pointers[512], &pointers[334], &pointers[964], &pointers[922], &pointers[1495], &pointers[634], &pointers[149], &pointers[14], &pointers[1724], &pointers[1384], &pointers[162], &pointers[1081], &pointers[1438], &pointers[255], &pointers[783], &pointers[1433], &pointers[1204], &pointers[892], &pointers[732], &pointers[574], &pointers[647], &pointers[614], &pointers[203], &pointers[1356], &pointers[1668], &pointers[41], &pointers[1127], &pointers[1171], &pointers[1207], &pointers[450], &pointers[207], &pointers[679], &pointers[1117], &pointers[481], &pointers[1507], &pointers[1240], &pointers[1369], &pointers[361], &pointers[990], &pointers[264], &pointers[811], &pointers[501], &pointers[228],
    &pointers[693], &pointers[139], &pointers[1602], &pointers[1652], &pointers[1248], &pointers[1322], &pointers[81], &pointers[1205], &pointers[13], &pointers[193], &pointers[545], &pointers[893], &pointers[1323], &pointers[539], &pointers[930], &pointers[927], &pointers[601], &pointers[602], &pointers[943], &pointers[181], &pointers[1280], &pointers[1048], &pointers[413], &pointers[137], &pointers[833], &pointers[100], &pointers[102], &pointers[1412], &pointers[1095], &pointers[1347], &pointers[1237], &pointers[165], &pointers[590], &pointers[752], &pointers[608], &pointers[781], &pointers[1526], &pointers[1582], &pointers[409], &pointers[570], &pointers[499], &pointers[1662], &pointers[1224], &pointers[1733], &pointers[77], &pointers[651], &pointers[1275], &pointers[813], &pointers[444], &pointers[1156],
    &pointers[1159], &pointers[1523], &pointers[1422], &pointers[1619], &pointers[552], &pointers[1058], &pointers[447], &pointers[104], &pointers[902], &pointers[22], &pointers[186], &pointers[452], &pointers[1690], &pointers[316], &pointers[1679], &pointers[726], &pointers[1336], &pointers[1217], &pointers[98], &pointers[106], &pointers[735], &pointers[146], &pointers[199], &pointers[559], &pointers[508], &pointers[1130], &pointers[1210], &pointers[383], &pointers[74], &pointers[551], &pointers[1211], &pointers[587], &pointers[669], &pointers[1600], &pointers[629], &pointers[1354], &pointers[733], &pointers[269], &pointers[1215], &pointers[868], &pointers[1128], &pointers[313], &pointers[1469], &pointers[1314], &pointers[983], &pointers[319], &pointers[774], &pointers[796], &pointers[504], &pointers[1502],
    &pointers[610], &pointers[797], &pointers[1483], &pointers[152], &pointers[670], &pointers[1000], &pointers[1609], &pointers[310], &pointers[620], &pointers[1685], &pointers[1727], &pointers[1633], &pointers[359], &pointers[1216], &pointers[333], &pointers[1593], &pointers[1261], &pointers[75], &pointers[770], &pointers[798], &pointers[1656], &pointers[1249], &pointers[1062], &pointers[1544], &pointers[382], &pointers[167], &pointers[284], &pointers[1598], &pointers[1539], &pointers[611], &pointers[221], &pointers[446], &pointers[672], &pointers[533], &pointers[112], &pointers[442], &pointers[1632], &pointers[1041], &pointers[689], &pointers[948], &pointers[511], &pointers[141], &pointers[1060], &pointers[138], &pointers[591], &pointers[871], &pointers[1383], &pointers[362], &pointers[200], &pointers[476],
    &pointers[753], &pointers[1738], &pointers[198], &pointers[40], &pointers[370], &pointers[940], &pointers[1658], &pointers[1631], &pointers[296], &pointers[800], &pointers[1331], &pointers[17], &pointers[1474], &pointers[867], &pointers[858], &pointers[1256], &pointers[908], &pointers[1430], &pointers[1193], &pointers[1634], &pointers[598], &pointers[127], &pointers[822], &pointers[898], &pointers[1578], &pointers[1500], &pointers[1335], &pointers[1169], &pointers[668], &pointers[1415], &pointers[1627], &pointers[696], &pointers[756], &pointers[148], &pointers[1004], &pointers[692], &pointers[278], &pointers[1309], &pointers[1133], &pointers[449], &pointers[1601], &pointers[344], &pointers[841], &pointers[1054], &pointers[674], &pointers[1489], &pointers[1545], &pointers[1144], &pointers[1028], &pointers[1020],
    &pointers[1098], &pointers[891], &pointers[1613], &pointers[1080], &pointers[1350], &pointers[1462], &pointers[566], &pointers[829], &pointers[1441], &pointers[637], &pointers[714], &pointers[1303], &pointers[1705], &pointers[1192], &pointers[1678], &pointers[745], &pointers[1448], &pointers[919], &pointers[622], &pointers[1726], &pointers[371], &pointers[445], &pointers[784], &pointers[1618], &pointers[226], &pointers[1236], &pointers[1451], &pointers[195], &pointers[64], &pointers[329], &pointers[1032], &pointers[115], &pointers[111], &pointers[395], &pointers[130], &pointers[936], &pointers[406], &pointers[414], &pointers[870], &pointers[1467], &pointers[944], &pointers[421], &pointers[657], &pointers[1450], &pointers[289], &pointers[273], &pointers[1233], &pointers[468], &pointers[407], &pointers[299],
    &pointers[1635], &pointers[1510], &pointers[288], &pointers[865], &pointers[688], &pointers[318], &pointers[448], &pointers[436], &pointers[1570], &pointers[1108], &pointers[1150], &pointers[1209], &pointers[125], &pointers[233], &pointers[194], &pointers[906], &pointers[252], &pointers[1744], &pointers[267], &pointers[950], &pointers[295], &pointers[1320], &pointers[954], &pointers[1482], &pointers[1516], &pointers[1446], &pointers[965], &pointers[169], &pointers[1420], &pointers[9], &pointers[1167], &pointers[632], &pointers[1672], &pointers[1145], &pointers[126], &pointers[27], &pointers[915], &pointers[946], &pointers[182], &pointers[1291], &pointers[55], &pointers[625], &pointers[1573], &pointers[94], &pointers[404], &pointers[695], &pointers[1373], &pointers[1228], &pointers[835], &pointers[1183]};

#endif

#ifdef POINTER_SIZE_2000
#ifdef FUNCTIONS_DATA_ON_CCM
  __attribute__((section(".ccmram")))
#endif
#ifdef FUNCTIONS_DATA_ON_FLASH
  const
#endif
   void *
#ifdef FUNCTIONS_DATA_ON_FLASH
  const
#endif
    pointers[2000] = {
    &pointers[1276], &pointers[875], &pointers[718], &pointers[1416], &pointers[1785], &pointers[1786], &pointers[517], &pointers[1221], &pointers[1167], &pointers[1906], &pointers[467], &pointers[429], &pointers[1299], &pointers[1866], &pointers[1780], &pointers[1381], &pointers[171], &pointers[120], &pointers[1021], &pointers[928], &pointers[1466], &pointers[1959], &pointers[1107], &pointers[358], &pointers[972], &pointers[1108], &pointers[1550], &pointers[1498], &pointers[984], &pointers[85], &pointers[1570], &pointers[870], &pointers[153], &pointers[1318], &pointers[259], &pointers[474], &pointers[1658], &pointers[1348], &pointers[1125], &pointers[1342], &pointers[619], &pointers[654], &pointers[345], &pointers[500], &pointers[62], &pointers[740], &pointers[1448], &pointers[1536], &pointers[98], &pointers[250],
    &pointers[1838], &pointers[1473], &pointers[1178], &pointers[683], &pointers[1926], &pointers[951], &pointers[1835], &pointers[401], &pointers[906], &pointers[1322], &pointers[1722], &pointers[1111], &pointers[1286], &pointers[1098], &pointers[1234], &pointers[584], &pointers[487], &pointers[201], &pointers[1642], &pointers[412], &pointers[131], &pointers[1556], &pointers[1324], &pointers[1232], &pointers[851], &pointers[6], &pointers[887], &pointers[181], &pointers[399], &pointers[1270], &pointers[1535], &pointers[1526], &pointers[280], &pointers[699], &pointers[1244], &pointers[632], &pointers[966], &pointers[1669], &pointers[286], &pointers[1327], &pointers[1138], &pointers[1549], &pointers[1016], &pointers[1258], &pointers[1551], &pointers[918], &pointers[1907], &pointers[1483], &pointers[263], &pointers[1998],
    &pointers[166], &pointers[253], &pointers[1583], &pointers[218], &pointers[1019], &pointers[1228], &pointers[78], &pointers[1846], &pointers[426], &pointers[1153], &pointers[309], &pointers[274], &pointers[1806], &pointers[1581], &pointers[109], &pointers[1308], &pointers[216], &pointers[525], &pointers[1170], &pointers[303], &pointers[491], &pointers[1887], &pointers[823], &pointers[1645], &pointers[99], &pointers[1876], &pointers[1997], &pointers[174], &pointers[1013], &pointers[1739], &pointers[1610], &pointers[1345], &pointers[234], &pointers[1730], &pointers[680], &pointers[1307], &pointers[635], &pointers[1248], &pointers[1275], &pointers[42], &pointers[1921], &pointers[472], &pointers[855], &pointers[1350], &pointers[1142], &pointers[1313], &pointers[768], &pointers[1392], &pointers[285], &pointers[1452],
    &pointers[755], &pointers[818], &pointers[311], &pointers[119], &pointers[1150], &pointers[440], &pointers[377], &pointers[1112], &pointers[666], &pointers[158], &pointers[33], &pointers[1284], &pointers[1474], &pointers[1071], &pointers[1792], &pointers[1521], &pointers[1231], &pointers[1948], &pointers[1482], &pointers[1262], &pointers[163], &pointers[1128], &pointers[1007], &pointers[1937], &pointers[469], &pointers[129], &pointers[1035], &pointers[599], &pointers[1110], &pointers[1386], &pointers[1378], &pointers[534], &pointers[1436], &pointers[1008], &pointers[1012], &pointers[1515], &pointers[1529], &pointers[427], &pointers[645], &pointers[640], &pointers[1763], &pointers[300], &pointers[432], &pointers[1287], &pointers[480], &pointers[605], &pointers[550], &pointers[89], &pointers[318], &pointers[1528],
    &pointers[1618], &pointers[1729], &pointers[1409], &pointers[577], &pointers[29], &pointers[393], &pointers[682], &pointers[1462], &pointers[865], &pointers[1176], &pointers[169], &pointers[653], &pointers[1689], &pointers[1949], &pointers[1672], &pointers[556], &pointers[14], &pointers[1399], &pointers[1764], &pointers[346], &pointers[834], &pointers[1408], &pointers[1208], &pointers[1682], &pointers[1619], &pointers[319], &pointers[569], &pointers[650], &pointers[276], &pointers[676], &pointers[281], &pointers[773], &pointers[762], &pointers[1147], &pointers[974], &pointers[1301], &pointers[1772], &pointers[1953], &pointers[172], &pointers[1493], &pointers[48], &pointers[1359], &pointers[665], &pointers[34], &pointers[1548], &pointers[1096], &pointers[456], &pointers[583], &pointers[786], &pointers[31],
    &pointers[1352], &pointers[1654], &pointers[1064], &pointers[251], &pointers[1898], &pointers[1541], &pointers[1038], &pointers[1842], &pointers[1479], &pointers[616], &pointers[271], &pointers[598], &pointers[792], &pointers[359], &pointers[523], &pointers[859], &pointers[1100], &pointers[658], &pointers[1499], &pointers[39], &pointers[58], &pointers[4], &pointers[1292], &pointers[1247], &pointers[227], &pointers[915], &pointers[600], &pointers[1061], &pointers[1760], &pointers[197], &pointers[804], &pointers[866], &pointers[538], &pointers[943], &pointers[1781], &pointers[1266], &pointers[613], &pointers[1280], &pointers[87], &pointers[667], &pointers[929], &pointers[1085], &pointers[1978], &pointers[339], &pointers[1859], &pointers[1628], &pointers[357], &pointers[1126], &pointers[1968], &pointers[541],
    &pointers[1891], &pointers[231], &pointers[1963], &pointers[1040], &pointers[697], &pointers[1477], &pointers[121], &pointers[375], &pointers[919], &pointers[1437], &pointers[1165], &pointers[1099], &pointers[1131], &pointers[1403], &pointers[820], &pointers[872], &pointers[1026], &pointers[1478], &pointers[12], &pointers[1166], &pointers[242], &pointers[843], &pointers[232], &pointers[1406], &pointers[1762], &pointers[1188], &pointers[1592], &pointers[1561], &pointers[1202], &pointers[970], &pointers[396], &pointers[1475], &pointers[155], &pointers[712], &pointers[609], &pointers[69], &pointers[1218], &pointers[462], &pointers[435], &pointers[980], &pointers[1787], &pointers[593], &pointers[516], &pointers[220], &pointers[156], &pointers[1945], &pointers[890], &pointers[1070], &pointers[93], &pointers[623],
    &pointers[333], &pointers[295], &pointers[1264], &pointers[1182], &pointers[1410], &pointers[1001], &pointers[1823], &pointers[545], &pointers[1757], &pointers[1065], &pointers[428], &pointers[117], &pointers[744], &pointers[940], &pointers[1636], &pointers[626], &pointers[1190], &pointers[1018], &pointers[1285], &pointers[183], &pointers[1293], &pointers[1278], &pointers[989], &pointers[1877], &pointers[703], &pointers[1843], &pointers[684], &pointers[845], &pointers[959], &pointers[986], &pointers[1790], &pointers[1082], &pointers[415], &pointers[255], &pointers[1195], &pointers[1494], &pointers[1089], &pointers[886], &pointers[1754], &pointers[1819], &pointers[877], &pointers[950], &pointers[30], &pointers[1524], &pointers[235], &pointers[1245], &pointers[1463], &pointers[1749], &pointers[1143], &pointers[1366],
    &pointers[388], &pointers[328], &pointers[1441], &pointers[244], &pointers[1831], &pointers[670], &pointers[1513], &pointers[742], &pointers[1105], &pointers[664], &pointers[1522], &pointers[1211], &pointers[52], &pointers[677], &pointers[1899], &pointers[1661], &pointers[1252], &pointers[1394], &pointers[1788], &pointers[488], &pointers[1962], &pointers[1449], &pointers[1958], &pointers[1024], &pointers[1874], &pointers[268], &pointers[3], &pointers[698], &pointers[1414], &pointers[1585], &pointers[102], &pointers[1870], &pointers[32], &pointers[1384], &pointers[287], &pointers[1407], &pointers[956], &pointers[90], &pointers[362], &pointers[1538], &pointers[36], &pointers[1651], &pointers[340], &pointers[1256], &pointers[836], &pointers[1745], &pointers[1773], &pointers[1351], &pointers[1738], &pointers[1555],
    &pointers[182], &pointers[1653], &pointers[540], &pointers[1638], &pointers[1912], &pointers[247], &pointers[83], &pointers[238], &pointers[249], &pointers[1136], &pointers[1487], &pointers[1560], &pointers[921], &pointers[1885], &pointers[1920], &pointers[44], &pointers[1314], &pointers[1268], &pointers[945], &pointers[686], &pointers[1878], &pointers[416], &pointers[548], &pointers[1862], &pointers[1081], &pointers[215], &pointers[537], &pointers[1343], &pointers[385], &pointers[173], &pointers[661], &pointers[761], &pointers[594], &pointers[521], &pointers[824], &pointers[314], &pointers[1006], &pointers[1517], &pointers[1471], &pointers[799], &pointers[760], &pointers[363], &pointers[335], &pointers[360], &pointers[901], &pointers[751], &pointers[896], &pointers[142], &pointers[553], &pointers[1798],
    &pointers[1340], &pointers[94], &pointers[1198], &pointers[1604], &pointers[1679], &pointers[780], &pointers[1288], &pointers[1639], &pointers[391], &pointers[128], &pointers[1212], &pointers[1330], &pointers[711], &pointers[934], &pointers[1589], &pointers[1635], &pointers[159], &pointers[1134], &pointers[1382], &pointers[1952], &pointers[671], &pointers[581], &pointers[763], &pointers[681], &pointers[1520], &pointers[47], &pointers[1465], &pointers[776], &pointers[1908], &pointers[35], &pointers[95], &pointers[1572], &pointers[1317], &pointers[1518], &pointers[1660], &pointers[212], &pointers[894], &pointers[1813], &pointers[1453], &pointers[453], &pointers[1960], &pointers[134], &pointers[1810], &pointers[1577], &pointers[389], &pointers[1294], &pointers[883], &pointers[1485], &pointers[175], &pointers[317],
    &pointers[1347], &pointers[229], &pointers[800], &pointers[852], &pointers[1703], &pointers[1476], &pointers[402], &pointers[478], &pointers[1056], &pointers[1751], &pointers[1421], &pointers[949], &pointers[597], &pointers[1302], &pointers[147], &pointers[1439], &pointers[1946], &pointers[965], &pointers[1461], &pointers[1418], &pointers[719], &pointers[840], &pointers[1827], &pointers[373], &pointers[118], &pointers[1845], &pointers[1711], &pointers[409], &pointers[381], &pointers[1817], &pointers[1417], &pointers[1059], &pointers[225], &pointers[144], &pointers[1519], &pointers[70], &pointers[1539], &pointers[294], &pointers[1986], &pointers[1694], &pointers[113], &pointers[1122], &pointers[1673], &pointers[643], &pointers[1438], &pointers[1137], &pointers[455], &pointers[963], &pointers[570], &pointers[660],
    &pointers[897], &pointers[721], &pointers[1840], &pointers[539], &pointers[290], &pointers[1837], &pointers[76], &pointers[1385], &pointers[1966], &pointers[105], &pointers[868], &pointers[1431], &pointers[45], &pointers[704], &pointers[1742], &pointers[1215], &pointers[579], &pointers[1017], &pointers[1675], &pointers[355], &pointers[1872], &pointers[1663], &pointers[1910], &pointers[1391], &pointers[1263], &pointers[1728], &pointers[1383], &pointers[985], &pointers[364], &pointers[330], &pointers[1753], &pointers[913], &pointers[1120], &pointers[349], &pointers[991], &pointers[728], &pointers[1273], &pointers[293], &pointers[992], &pointers[378], &pointers[1405], &pointers[1181], &pointers[1553], &pointers[408], &pointers[819], &pointers[1230], &pointers[1681], &pointers[379], &pointers[1784], &pointers[628],
    &pointers[372], &pointers[982], &pointers[1992], &pointers[406], &pointers[630], &pointers[460], &pointers[560], &pointers[1373], &pointers[1468], &pointers[869], &pointers[853], &pointers[394], &pointers[585], &pointers[1489], &pointers[1851], &pointers[1566], &pointers[1184], &pointers[1290], &pointers[1376], &pointers[542], &pointers[1850], &pointers[546], &pointers[65], &pointers[1420], &pointers[463], &pointers[367], &pointers[177], &pointers[1428], &pointers[1102], &pointers[302], &pointers[618], &pointers[1233], &pointers[939], &pointers[1484], &pointers[1527], &pointers[1718], &pointers[752], &pointers[63], &pointers[400], &pointers[1612], &pointers[321], &pointers[702], &pointers[655], &pointers[136], &pointers[369], &pointers[657], &pointers[1709], &pointers[565], &pointers[1051], &pointers[165],
    &pointers[1442], &pointers[1503], &pointers[829], &pointers[1160], &pointers[1999], &pointers[1693], &pointers[1050], &pointers[881], &pointers[1512], &pointers[765], &pointers[1620], &pointers[960], &pointers[969], &pointers[1712], &pointers[1], &pointers[791], &pointers[1458], &pointers[354], &pointers[831], &pointers[494], &pointers[779], &pointers[265], &pointers[1801], &pointers[1490], &pointers[1344], &pointers[164], &pointers[482], &pointers[1829], &pointers[1677], &pointers[1423], &pointers[1841], &pointers[713], &pointers[893], &pointers[1731], &pointers[607], &pointers[1629], &pointers[1973], &pointers[1593], &pointers[1309], &pointers[730], &pointers[850], &pointers[1683], &pointers[978], &pointers[304], &pointers[230], &pointers[1146], &pointers[639], &pointers[1799], &pointers[1027], &pointers[167],
    &pointers[771], &pointers[1603], &pointers[1707], &pointers[1761], &pointers[1402], &pointers[1154], &pointers[648], &pointers[958], &pointers[261], &pointers[210], &pointers[185], &pointers[1774], &pointers[961], &pointers[1339], &pointers[306], &pointers[1319], &pointers[2], &pointers[1804], &pointers[1821], &pointers[669], &pointers[880], &pointers[1185], &pointers[1775], &pointers[1684], &pointers[458], &pointers[1537], &pointers[176], &pointers[1744], &pointers[787], &pointers[1357], &pointers[1114], &pointers[1758], &pointers[1206], &pointers[1857], &pointers[1674], &pointers[612], &pointers[1092], &pointers[326], &pointers[110], &pointers[535], &pointers[975], &pointers[775], &pointers[186], &pointers[365], &pointers[1710], &pointers[1608], &pointers[1854], &pointers[1759], &pointers[327], &pointers[1858],
    &pointers[1430], &pointers[356], &pointers[450], &pointers[1398], &pointers[28], &pointers[1501], &pointers[707], &pointers[1964], &pointers[944], &pointers[1573], &pointers[1691], &pointers[1377], &pointers[1977], &pointers[64], &pointers[124], &pointers[674], &pointers[673], &pointers[1668], &pointers[1979], &pointers[1497], &pointers[847], &pointers[716], &pointers[746], &pointers[1698], &pointers[88], &pointers[386], &pointers[1333], &pointers[301], &pointers[38], &pointers[1666], &pointers[997], &pointers[571], &pointers[66], &pointers[1049], &pointers[917], &pointers[914], &pointers[573], &pointers[717], &pointers[1005], &pointers[1155], &pointers[236], &pointers[348], &pointers[1727], &pointers[1665], &pointers[512], &pointers[1632], &pointers[1080], &pointers[1028], &pointers[219], &pointers[1824],
    &pointers[1941], &pointers[953], &pointers[1972], &pointers[223], &pointers[352], &pointers[532], &pointers[1097], &pointers[350], &pointers[750], &pointers[839], &pointers[108], &pointers[528], &pointers[604], &pointers[1229], &pointers[1918], &pointers[1735], &pointers[624], &pointers[1171], &pointers[1637], &pointers[1984], &pointers[411], &pointers[1144], &pointers[1200], &pointers[1552], &pointers[1220], &pointers[1766], &pointers[1219], &pointers[971], &pointers[1349], &pointers[257], &pointers[885], &pointers[1692], &pointers[1664], &pointers[1325], &pointers[1734], &pointers[1646], &pointers[692], &pointers[187], &pointers[1685], &pointers[1205], &pointers[764], &pointers[924], &pointers[957], &pointers[529], &pointers[1987], &pointers[942], &pointers[1054], &pointers[307], &pointers[1169], &pointers[122],
    &pointers[1289], &pointers[353], &pointers[1902], &pointers[899], &pointers[1279], &pointers[1446], &pointers[1547], &pointers[722], &pointers[1157], &pointers[503], &pointers[1655], &pointers[567], &pointers[260], &pointers[1048], &pointers[1736], &pointers[638], &pointers[1750], &pointers[531], &pointers[1213], &pointers[1241], &pointers[459], &pointers[610], &pointers[747], &pointers[1033], &pointers[861], &pointers[490], &pointers[374], &pointers[421], &pointers[96], &pointers[1271], &pointers[492], &pointers[1464], &pointers[813], &pointers[1756], &pointers[1334], &pointers[1194], &pointers[967], &pointers[1627], &pointers[611], &pointers[170], &pointers[1778], &pointers[1558], &pointers[16], &pointers[387], &pointers[1881], &pointers[1509], &pointers[205], &pointers[706], &pointers[222], &pointers[592],
    &pointers[1015], &pointers[1696], &pointers[15], &pointers[720], &pointers[1590], &pointers[1596], &pointers[938], &pointers[1574], &pointers[292], &pointers[741], &pointers[1856], &pointers[1779], &pointers[312], &pointers[827], &pointers[1372], &pointers[1187], &pointers[464], &pointers[320], &pointers[1444], &pointers[200], &pointers[1337], &pointers[1765], &pointers[1121], &pointers[1690], &pointers[207], &pointers[803], &pointers[1306], &pointers[1936], &pointers[580], &pointers[1597], &pointers[1424], &pointers[895], &pointers[562], &pointers[1451], &pointers[1091], &pointers[1427], &pointers[968], &pointers[790], &pointers[1815], &pointers[397], &pointers[180], &pointers[331], &pointers[1338], &pointers[1072], &pointers[114], &pointers[543], &pointers[795], &pointers[101], &pointers[801], &pointers[1545],
    &pointers[1411], &pointers[572], &pointers[1393], &pointers[1395], &pointers[549], &pointers[316], &pointers[1836], &pointers[434], &pointers[558], &pointers[1246], &pointers[518], &pointers[685], &pointers[996], &pointers[821], &pointers[863], &pointers[1557], &pointers[1733], &pointers[515], &pointers[1455], &pointers[814], &pointers[678], &pointers[1454], &pointers[246], &pointers[694], &pointers[190], &pointers[1326], &pointers[1199], &pointers[578], &pointers[77], &pointers[501], &pointers[1922], &pointers[933], &pointers[1606], &pointers[439], &pointers[5], &pointers[1844], &pointers[595], &pointers[1083], &pointers[1559], &pointers[461], &pointers[1657], &pointers[1172], &pointers[825], &pointers[338], &pointers[430], &pointers[296], &pointers[22], &pointers[67], &pointers[1116], &pointers[1565],
    &pointers[727], &pointers[1251], &pointers[1601], &pointers[10], &pointers[1365], &pointers[1361], &pointers[1602], &pointers[1971], &pointers[1364], &pointers[1643], &pointers[1771], &pointers[191], &pointers[291], &pointers[1158], &pointers[557], &pointers[564], &pointers[40], &pointers[1752], &pointers[1687], &pointers[133], &pointers[1974], &pointers[903], &pointers[1833], &pointers[679], &pointers[589], &pointers[514], &pointers[1970], &pointers[1897], &pointers[688], &pointers[497], &pointers[590], &pointers[879], &pointers[923], &pointers[1191], &pointers[1486], &pointers[1939], &pointers[60], &pointers[61], &pointers[1355], &pointers[479], &pointers[368], &pointers[1148], &pointers[23], &pointers[832], &pointers[468], &pointers[240], &pointers[1067], &pointers[1163], &pointers[151], &pointers[433],
    &pointers[168], &pointers[196], &pointers[315], &pointers[757], &pointers[849], &pointers[1795], &pointers[1888], &pointers[1567], &pointers[981], &pointers[1820], &pointers[332], &pointers[788], &pointers[233], &pointers[908], &pointers[209], &pointers[1996], &pointers[1582], &pointers[189], &pointers[392], &pointers[9], &pointers[659], &pointers[1943], &pointers[844], &pointers[1030], &pointers[1063], &pointers[1614], &pointers[1388], &pointers[1257], &pointers[152], &pointers[1680], &pointers[483], &pointers[1867], &pointers[732], &pointers[1743], &pointers[1808], &pointers[1164], &pointers[237], &pointers[1613], &pointers[1580], &pointers[1300], &pointers[1043], &pointers[1662], &pointers[18], &pointers[1989], &pointers[544], &pointers[80], &pointers[1443], &pointers[1975], &pointers[1702], &pointers[633],
    &pointers[1961], &pointers[1708], &pointers[270], &pointers[796], &pointers[925], &pointers[1316], &pointers[272], &pointers[59], &pointers[1500], &pointers[1260], &pointers[1037], &pointers[50], &pointers[1113], &pointers[1976], &pointers[8], &pointers[1650], &pointers[1879], &pointers[254], &pointers[1207], &pointers[527], &pointers[1481], &pointers[772], &pointers[1510], &pointers[1721], &pointers[1791], &pointers[441], &pointers[1982], &pointers[1882], &pointers[473], &pointers[1825], &pointers[1243], &pointers[266], &pointers[1796], &pointers[91], &pointers[1460], &pointers[1723], &pointers[1649], &pointers[383], &pointers[749], &pointers[1892], &pointers[24], &pointers[1622], &pointers[1605], &pointers[1869], &pointers[1890], &pointers[470], &pointers[1927], &pointers[1563], &pointers[1523], &pointers[1852],
    &pointers[1109], &pointers[7], &pointers[904], &pointers[1084], &pointers[1360], &pointers[1433], &pointers[1224], &pointers[1422], &pointers[1533], &pointers[419], &pointers[1793], &pointers[1459], &pointers[410], &pointers[245], &pointers[1175], &pointers[1066], &pointers[1132], &pointers[705], &pointers[1584], &pointers[1179], &pointers[445], &pointers[1933], &pointers[184], &pointers[298], &pointers[1818], &pointers[1934], &pointers[937], &pointers[1140], &pointers[806], &pointers[1894], &pointers[1003], &pointers[1093], &pointers[1688], &pointers[325], &pointers[198], &pointers[1595], &pointers[1201], &pointers[243], &pointers[709], &pointers[793], &pointers[838], &pointers[1811], &pointers[1119], &pointers[1101], &pointers[390], &pointers[1886], &pointers[973], &pointers[1847], &pointers[1429], &pointers[1861],
    &pointers[990], &pointers[743], &pointers[1616], &pointers[1954], &pointers[1088], &pointers[1079], &pointers[1807], &pointers[1914], &pointers[1124], &pointers[1323], &pointers[1935], &pointers[384], &pointers[160], &pointers[297], &pointers[1599], &pointers[912], &pointers[1265], &pointers[465], &pointers[873], &pointers[878], &pointers[423], &pointers[1746], &pointers[452], &pointers[1014], &pointers[909], &pointers[437], &pointers[524], &pointers[1805], &pointers[403], &pointers[1332], &pointers[1571], &pointers[1719], &pointers[420], &pointers[72], &pointers[305], &pointers[1023], &pointers[781], &pointers[486], &pointers[614], &pointers[1911], &pointers[1794], &pointers[1814], &pointers[1883], &pointers[1472], &pointers[1068], &pointers[1329], &pointers[1924], &pointers[1238], &pointers[1358], &pointers[1010],
    &pointers[1152], &pointers[631], &pointers[1168], &pointers[782], &pointers[1502], &pointers[555], &pointers[916], &pointers[343], &pointers[68], &pointers[150], &pointers[1507], &pointers[1346], &pointers[1713], &pointers[1046], &pointers[1129], &pointers[436], &pointers[1103], &pointers[1957], &pointers[1740], &pointers[1115], &pointers[708], &pointers[1237], &pointers[1401], &pointers[228], &pointers[976], &pointers[551], &pointers[1380], &pointers[910], &pointers[1895], &pointers[987], &pointers[107], &pointers[366], &pointers[1873], &pointers[157], &pointers[864], &pointers[519], &pointers[1889], &pointers[1947], &pointers[79], &pointers[84], &pointers[1504], &pointers[1404], &pointers[700], &pointers[723], &pointers[767], &pointers[1141], &pointers[1335], &pointers[351], &pointers[25], &pointers[1985],
    &pointers[1930], &pointers[262], &pointers[1274], &pointers[777], &pointers[405], &pointers[1440], &pointers[1623], &pointers[1253], &pointers[1588], &pointers[1413], &pointers[71], &pointers[1135], &pointers[1993], &pointers[73], &pointers[1782], &pointers[258], &pointers[1042], &pointers[46], &pointers[489], &pointers[576], &pointers[591], &pointers[135], &pointers[424], &pointers[139], &pointers[1496], &pointers[1542], &pointers[561], &pointers[199], &pointers[1659], &pointers[754], &pointers[1634], &pointers[979], &pointers[1022], &pointers[884], &pointers[1748], &pointers[888], &pointers[342], &pointers[1944], &pointers[1863], &pointers[1282], &pointers[1875], &pointers[496], &pointers[1965], &pointers[826], &pointers[1315], &pointers[724], &pointers[994], &pointers[1210], &pointers[1871], &pointers[239],
    &pointers[1077], &pointers[1419], &pointers[1186], &pointers[275], &pointers[1826], &pointers[649], &pointers[1447], &pointers[1151], &pointers[1118], &pointers[1670], &pointers[922], &pointers[1495], &pointers[634], &pointers[1183], &pointers[882], &pointers[1931], &pointers[1375], &pointers[162], &pointers[588], &pointers[43], &pointers[625], &pointers[417], &pointers[1047], &pointers[1204], &pointers[1884], &pointers[1951], &pointers[21], &pointers[647], &pointers[1180], &pointers[493], &pointers[748], &pointers[1387], &pointers[1254], &pointers[526], &pointers[867], &pointers[264], &pointers[54], &pointers[457], &pointers[1506], &pointers[1117], &pointers[123], &pointers[1240], &pointers[1174], &pointers[1369], &pointers[361], &pointers[830], &pointers[329], &pointers[536], &pointers[56], &pointers[1586],
    &pointers[693], &pointers[778], &pointers[447], &pointers[662], &pointers[395], &pointers[277], &pointers[615], &pointers[192], &pointers[1607], &pointers[1492], &pointers[736], &pointers[1725], &pointers[51], &pointers[112], &pointers[1991], &pointers[1226], &pointers[179], &pointers[602], &pointers[1832], &pointers[889], &pointers[1032], &pointers[766], &pointers[86], &pointers[1609], &pointers[1374], &pointers[100], &pointers[57], &pointers[1412], &pointers[586], &pointers[1699], &pointers[178], &pointers[1514], &pointers[502], &pointers[1525], &pointers[1445], &pointers[554], &pointers[1223], &pointers[1469], &pointers[1755], &pointers[1087], &pointers[1173], &pointers[1900], &pointers[1311], &pointers[1913], &pointers[1296], &pointers[651], &pointers[854], &pointers[1980], &pointers[444], &pointers[1156],
    &pointers[193], &pointers[1942], &pointers[224], &pointers[508], &pointers[1002], &pointers[1705], &pointers[715], &pointers[1630], &pointers[1295], &pointers[1676], &pointers[520], &pointers[1269], &pointers[1697], &pointers[1192], &pointers[817], &pointers[931], &pointers[1336], &pointers[1217], &pointers[617], &pointers[642], &pointers[735], &pointers[1938], &pointers[1615], &pointers[1540], &pointers[1956], &pointers[1789], &pointers[1896], &pointers[448], &pointers[1802], &pointers[1562], &pointers[104], &pointers[596], &pointers[1726], &pointers[1600], &pointers[663], &pointers[1239], &pointers[733], &pointers[734], &pointers[1686], &pointers[1009], &pointers[1839], &pointers[103], &pointers[1656], &pointers[145], &pointers[1216], &pointers[1816], &pointers[1055], &pointers[1671], &pointers[504], &pointers[308],
    &pointers[920], &pointers[932], &pointers[1967], &pointers[656], &pointers[337], &pointers[1834], &pointers[1901], &pointers[1578], &pointers[1893], &pointers[1368], &pointers[807], &pointers[1633], &pointers[1162], &pointers[1139], &pointers[689], &pointers[1045], &pointers[930], &pointers[809], &pointers[1069], &pointers[798], &pointers[876], &pointers[726], &pointers[1396], &pointers[1828], &pointers[116], &pointers[1432], &pointers[568], &pointers[1929], &pointers[1621], &pointers[466], &pointers[1353], &pointers[418], &pointers[1310], &pointers[477], &pointers[646], &pointers[442], &pointers[1631], &pointers[729], &pointers[1880], &pointers[948], &pointers[1932], &pointers[267], &pointers[1812], &pointers[132], &pointers[758], &pointers[710], &pointers[621], &pointers[241], &pointers[203], &pointers[1720],
    &pointers[1955], &pointers[955], &pointers[1123], &pointers[509], &pointers[82], &pointers[1950], &pointers[789], &pointers[1617], &pointers[323], &pointers[842], &pointers[1995], &pointers[874], &pointers[608], &pointers[1272], &pointers[858], &pointers[202], &pointers[1797], &pointers[1303], &pointers[1594], &pointers[454], &pointers[687], &pointers[739], &pointers[1371], &pointers[783], &pointers[1830], &pointers[1078], &pointers[559], &pointers[856], &pointers[1940], &pointers[1415], &pointers[1390], &pointers[1044], &pointers[1074], &pointers[148], &pointers[731], &pointers[41], &pointers[161], &pointers[336], &pointers[1737], &pointers[1267], &pointers[1769], &pointers[1094], &pointers[1011], &pointers[481], &pointers[1530], &pointers[475], &pointers[1800], &pointers[1644], &pointers[252], &pointers[1704],
    &pointers[1036], &pointers[811], &pointers[221], &pointers[816], &pointers[1259], &pointers[1903], &pointers[805], &pointers[1611], &pointers[1106], &pointers[641], &pointers[582], &pointers[81], &pointers[1544], &pointers[1783], &pointers[13], &pointers[1425], &pointers[204], &pointers[1648], &pointers[1426], &pointers[1457], &pointers[1197], &pointers[97], &pointers[530], &pointers[1025], &pointers[977], &pointers[1236], &pointers[905], &pointers[627], &pointers[26], &pointers[947], &pointers[927], &pointers[485], &pointers[1575], &pointers[137], &pointers[1090], &pointers[1060], &pointers[1491], &pointers[1370], &pointers[603], &pointers[1145], &pointers[1321], &pointers[900], &pointers[1255], &pointers[513], &pointers[1379], &pointers[794], &pointers[1747], &pointers[837], &pointers[1363], &pointers[398],
    &pointers[1039], &pointers[211], &pointers[499], &pointers[552], &pointers[563], &pointers[1905], &pointers[911], &pointers[1362], &pointers[476], &pointers[601], &pointers[1161], &pointers[995], &pointers[1320], &pointers[701], &pointers[1159], &pointers[1626], &pointers[256], &pointers[1624], &pointers[425], &pointers[725], &pointers[1058], &pointers[1532], &pointers[954], &pointers[19], &pointers[1516], &pointers[1057], &pointers[1225], &pointers[414], &pointers[283], &pointers[1261], &pointers[1543], &pointers[828], &pointers[1667], &pointers[279], &pointers[964], &pointers[1189], &pointers[106], &pointers[1291], &pointers[675], &pointers[53], &pointers[1701], &pointers[1848], &pointers[140], &pointers[1305], &pointers[574], &pointers[334], &pointers[347], &pointers[1397], &pointers[1196], &pointers[74],
    &pointers[566], &pointers[1700], &pointers[1990], &pointers[587], &pointers[769], &pointers[1034], &pointers[629], &pointers[774], &pointers[1149], &pointers[269], &pointers[738], &pointers[606], &pointers[1277], &pointers[672], &pointers[313], &pointers[941], &pointers[1511], &pointers[983], &pointers[498], &pointers[1470], &pointers[1969], &pointers[1214], &pointers[1717], &pointers[1104], &pointers[797], &pointers[1678], &pointers[282], &pointers[1569], &pointers[1203], &pointers[505], &pointers[1915], &pointers[310], &pointers[620], &pointers[214], &pointers[1923], &pointers[11], NULL, &pointers[341], &pointers[902], &pointers[1591], &pointers[1822], &pointers[1716], &pointers[1809], &pointers[75], &pointers[770], &pointers[1389], &pointers[812], &pointers[737], &pointers[1849], &pointers[1062],
    &pointers[1767], &pointers[636], &pointers[382], &pointers[988], &pointers[284], &pointers[92], &pointers[1706], &pointers[431], &pointers[1652], &pointers[446], &pointers[1031], &pointers[1052], &pointers[533], &pointers[20], &pointers[1488], &pointers[1865], &pointers[1076], &pointers[1564], &pointers[1598], &pointers[1554], &pointers[141], &pointers[962], &pointers[138], &pointers[891], &pointers[652], &pointers[1508], &pointers[1641], &pointers[451], &pointers[1304], &pointers[1075], &pointers[1127], &pointers[785], &pointers[1776], &pointers[127], &pointers[370], &pointers[1925], &pointers[1647], &pointers[1864], &pointers[324], &pointers[126], &pointers[1331], &pointers[17], &pointers[413], &pointers[380], &pointers[815], &pointers[1073], &pointers[322], &pointers[1853], &pointers[1193], &pointers[1868],
    &pointers[575], &pointers[1298], &pointers[1222], &pointers[1356], &pointers[1249], &pointers[926], &pointers[695], &pointers[1714], &pointers[1534], &pointers[49], &pointers[668], &pointers[1531], &pointers[822], &pointers[1029], &pointers[696], &pointers[756], &pointers[125], &pointers[226], &pointers[1004], &pointers[1328], &pointers[278], &pointers[1505], &pointers[1133], &pointers[449], &pointers[952], &pointers[344], &pointers[841], &pointers[1777], &pointers[1732], &pointers[1041], &pointers[1400], &pointers[143], &pointers[1297], &pointers[848], &pointers[1020], &pointers[1904], &pointers[1242], &pointers[862], &pointers[1434], &pointers[1086], &pointers[833], &pointers[1354], &pointers[857], &pointers[1177], &pointers[1283], &pointers[637], &pointers[714], &pointers[1367], &pointers[248], &pointers[1768],
    &pointers[1546], &pointers[745], &pointers[443], &pointers[1916], &pointers[1770], &pointers[622], &pointers[217], &pointers[371], &pointers[471], &pointers[784], &pointers[1741], &pointers[208], &pointers[484], &pointers[1456], &pointers[195], &pointers[149], &pointers[759], &pointers[299], &pointers[115], &pointers[892], &pointers[111], &pointers[1855], &pointers[130], &pointers[936], &pointers[1312], &pointers[1715], &pointers[1053], &pointers[808], &pointers[1994], &pointers[1467], &pointers[993], &pointers[1724], &pointers[511], &pointers[1450], &pointers[810], &pointers[289], &pointers[273], &pointers[1480], &pointers[691], &pointers[407], &pointers[1341], &pointers[1917], &pointers[1576], &pointers[1860], &pointers[288], &pointers[1095], &pointers[871], &pointers[213], &pointers[998], &pointers[860],
    &pointers[999], &pointers[438], &pointers[644], &pointers[1250], &pointers[1209], &pointers[753], &pointers[146], &pointers[194], &pointers[907], &pointers[188], &pointers[1130], &pointers[506], &pointers[1928], &pointers[898], &pointers[1981], &pointers[690], &pointers[1988], &pointers[422], &pointers[1983], &pointers[1227], &pointers[1919], &pointers[495], &pointers[522], &pointers[1579], &pointers[1000], &pointers[1435], &pointers[507], &pointers[935], &pointers[1909], &pointers[1640], &pointers[376], &pointers[1235], &pointers[27], &pointers[846], &pointers[206], &pointers[946], &pointers[1803], &pointers[1695], &pointers[55], &pointers[802], &pointers[1625], &pointers[1568], &pointers[37], &pointers[154], &pointers[404], &pointers[1587], &pointers[547], &pointers[510], &pointers[835], &pointers[1281]};
#endif
/* USER CODE END PM */

TIM_HandleTypeDef htim2;

UART_HandleTypeDef huart1;

void SystemClock_Config(void);
static void MX_GPIO_Init(void);
static void MX_TIM2_Init(void);
static void MX_USART1_UART_Init(void);

int main(void)
{
  /* USER CODE BEGIN 1 */
    int time1 __attribute__((aligned (4))) = 0;
    int time2 __attribute__((aligned (4))) = 0;

  //void **this_pp = p0;
  /* USER CODE END 1 */

  /* MCU Configuration--------------------------------------------------------*/

  /* Reset of all peripherals, Initializes the Flash interface and the Systick. */
  HAL_Init();

  /* Configure the system clock */
  SystemClock_Config();

  /* Initialize all configured peripherals */
  MX_GPIO_Init();
  MX_TIM2_Init();
  MX_USART1_UART_Init();
  /* USER CODE BEGIN 2 */
//  int n = 1000;
//  TIM2->CR1&=~TIM_CR1_DIR;

  // enable update interrupts
  TIM2->DIER|=TIM_DIER_UIE;
  //NVIC_EnableIRQ(TIM2_IRQn);

  //start the timer
  HAL_TIM_Base_Start(&htim2);
  //set the over flow counter to 0
  overflow_cnt = 0;

  time1 = TIM2->CNT;

  //pointer_chase starts
  random_pointer_chase_1000times(&(pointers[0]));

  time2 = TIM2->CNT;
  tim_cnt = time2 -time1;
  execution_time = overflow_cnt*1000 + (double)tim_cnt/(1000);
  //execution time is in ms
  uint8_t msg[40] = {'\0'};

  sprintf(msg,"\n\RandomPointerChase:\n\r%d", (int)(execution_time*1000));
  HAL_UART_Transmit(&huart1, msg, sizeof(msg), 0xffff);
  /* USER CODE END 2 */

  /* Infinite loop */
  /* USER CODE BEGIN WHILE */

  int i = 0;

  while (i<10)
{

	  MX_TIM2_Init();
	  HAL_TIM_Base_Start(&htim2);
	  overflow_cnt = 0;
	  time1 = TIM2->CNT;

	  random_pointer_chase_1000times(&(pointers[0]));

	  time2 = TIM2->CNT;
	  ////////////////////////////////////////////////////////////////////end counting time
	  tim_cnt = time2 -time1;
	  execution_time = overflow_cnt*1000 + (double)tim_cnt/(1000);

	  uint8_t msg[40] = {'\0'};

	  sprintf(msg,"\n\r%dth: RandomPointerChase:\n\r%d", i,(int)(execution_time*1000));
	  HAL_UART_Transmit(&huart1, msg, sizeof(msg), 0xffff);
	  i++;
    /* USER CODE END WHILE */

    /* USER CODE BEGIN 3 */
  }
  return 0;
  /* USER CODE END 3 */
}

void SystemClock_Config(void)
{
  RCC_OscInitTypeDef RCC_OscInitStruct = {0};
  RCC_ClkInitTypeDef RCC_ClkInitStruct = {0};
  RCC_PeriphCLKInitTypeDef PeriphClkInit = {0};

  /** Initializes the RCC Oscillators according to the specified parameters
  * in the RCC_OscInitTypeDef structure.
  */
  RCC_OscInitStruct.OscillatorType = RCC_OSCILLATORTYPE_HSE;
  RCC_OscInitStruct.HSEState = RCC_HSE_ON;
  RCC_OscInitStruct.HSEPredivValue = RCC_HSE_PREDIV_DIV1;
  RCC_OscInitStruct.HSIState = RCC_HSI_ON;
  RCC_OscInitStruct.PLL.PLLState = RCC_PLL_ON;
  RCC_OscInitStruct.PLL.PLLSource = RCC_PLLSOURCE_HSE;
  RCC_OscInitStruct.PLL.PLLMUL = RCC_PLL_MUL3;
  if (HAL_RCC_OscConfig(&RCC_OscInitStruct) != HAL_OK)
  {
    Error_Handler();
  }
  /** Initializes the CPU, AHB and APB buses clocks
  */
  RCC_ClkInitStruct.ClockType = RCC_CLOCKTYPE_HCLK|RCC_CLOCKTYPE_SYSCLK
                              |RCC_CLOCKTYPE_PCLK1|RCC_CLOCKTYPE_PCLK2;
  RCC_ClkInitStruct.SYSCLKSource = RCC_SYSCLKSOURCE_PLLCLK;
  RCC_ClkInitStruct.AHBCLKDivider = RCC_SYSCLK_DIV1;
  RCC_ClkInitStruct.APB1CLKDivider = RCC_HCLK_DIV2;
  RCC_ClkInitStruct.APB2CLKDivider = RCC_HCLK_DIV1;

  if (HAL_RCC_ClockConfig(&RCC_ClkInitStruct, FLASH_LATENCY_0) != HAL_OK)
  {
    Error_Handler();
  }
  PeriphClkInit.PeriphClockSelection = RCC_PERIPHCLK_USART1;
  PeriphClkInit.Usart1ClockSelection = RCC_USART1CLKSOURCE_PCLK2;
  if (HAL_RCCEx_PeriphCLKConfig(&PeriphClkInit) != HAL_OK)
  {
    Error_Handler();
  }
}

static void MX_TIM2_Init(void)
{

  TIM_ClockConfigTypeDef sClockSourceConfig = {0};
  TIM_MasterConfigTypeDef sMasterConfig = {0};

  htim2.Instance = TIM2;
  htim2.Init.Prescaler = (24-1);
  htim2.Init.CounterMode = TIM_COUNTERMODE_UP;
  htim2.Init.Period = (1000000-1);
  htim2.Init.ClockDivision = TIM_CLOCKDIVISION_DIV1;
  htim2.Init.AutoReloadPreload = TIM_AUTORELOAD_PRELOAD_DISABLE;
  if (HAL_TIM_Base_Init(&htim2) != HAL_OK)
  {
    Error_Handler();
  }
  sClockSourceConfig.ClockSource = TIM_CLOCKSOURCE_INTERNAL;
  if (HAL_TIM_ConfigClockSource(&htim2, &sClockSourceConfig) != HAL_OK)
  {
    Error_Handler();
  }
  sMasterConfig.MasterOutputTrigger = TIM_TRGO_RESET;
  sMasterConfig.MasterSlaveMode = TIM_MASTERSLAVEMODE_DISABLE;
  if (HAL_TIMEx_MasterConfigSynchronization(&htim2, &sMasterConfig) != HAL_OK)
  {
    Error_Handler();
  }

}

static void MX_USART1_UART_Init(void)
{

  huart1.Instance = USART1;
  huart1.Init.BaudRate = 38400;
  huart1.Init.WordLength = UART_WORDLENGTH_8B;
  huart1.Init.StopBits = UART_STOPBITS_1;
  huart1.Init.Parity = UART_PARITY_NONE;
  huart1.Init.Mode = UART_MODE_TX_RX;
  huart1.Init.HwFlowCtl = UART_HWCONTROL_NONE;
  huart1.Init.OverSampling = UART_OVERSAMPLING_16;
  huart1.Init.OneBitSampling = UART_ONE_BIT_SAMPLE_DISABLE;
  huart1.AdvancedInit.AdvFeatureInit = UART_ADVFEATURE_NO_INIT;
  if (HAL_UART_Init(&huart1) != HAL_OK)
  {
    Error_Handler();
  }

}

static void MX_GPIO_Init(void)
{

  /* GPIO Ports Clock Enable */
  __HAL_RCC_GPIOF_CLK_ENABLE();
  __HAL_RCC_GPIOC_CLK_ENABLE();

}

/* USER CODE BEGIN 4 */
void HAL_TIM_PeriodElapsedCallback(TIM_HandleTypeDef* htim)
{
	overflow_cnt++;

}

/* USER CODE END 4 */

void Error_Handler(void)
{
  __disable_irq();
  while (1)
  {
  }
}

/************************ (C) COPYRIGHT STMicroelectronics *****END OF FILE****/
